VERSION ""

NS_ :

BS_:

BU_: Vector__XXX

BO_ 512 SM_Heartbeat: 8 Vector__XXX
SG_ SM_State : 0|8@1+ (1,0) [0|255] "" Vector__XXX
SG_ SM_Vbatt : 8|8@1+ (0.066666,0) [0|16.99983] "V" Vector__XXX
SG_ Target_State : 16|8@1+ (1,0) [0|255] "" Vector__XXX
SG_ CC_Heartbeat_Timed_Out : 24|1@1+ (1,0) [0|1] "" Vector__XXX
SG_ FSM_Heartbeat_Timed_Out : 25|1@1+ (1,0) [0|1] "" Vector__XXX
SG_ RSM_Heartbeat_Timed_Out : 26|1@1+ (1,0) [0|1] "" Vector__XXX
SG_ DIM_Heartbeat_Timed_Out : 27|1@1+ (1,0) [0|1] "" Vector__XXX
SG_ AFC_Heartbeat_Timed_Out : 28|1@1+ (1,0) [0|1] "" Vector__XXX
SG_ TM_Heartbeat_Timed_Out : 29|1@1+ (1,0) [0|1] "" Vector__XXX
SG_ CC_State_Timed_Out : 32|1@1+ (1,0) [0|1] "" Vector__XXX
SG_ FSM_State_Timed_Out : 33|1@1+ (1,0) [0|1] "" Vector__XXX
SG_ RSM_State_Timed_Out : 34|1@1+ (1,0) [0|1] "" Vector__XXX
SG_ DIM_State_Timed_Out : 35|1@1+ (1,0) [0|1] "" Vector__XXX
SG_ AFC_State_Timed_Out : 36|1@1+ (1,0) [0|1] "" Vector__XXX
SG_ TM_State_Timed_Out : 37|1@1+ (1,0) [0|1] "" Vector__XXX
SG_ IMD_ERROR : 40|1@1+ (1,0) [0|1] "" Vector__XXX
SG_ BMS_Error : 41|1@1+ (1,0) [0|1] "" Vector__XXX
SG_ BSPD_Error : 42|1@1+ (1,0) [0|1] "" Vector__XXX
SG_ Egress : 44|1@1+ (1,0) [0|1] "" Vector__XXX
SG_ Check : 43|1@1+ (1,0) [0|1] "" Vector__XXX
SG_ DCDC_ERROR : 45|1@1+ (1,0) [0|1] "" Vector__XXX
SG_ Cooling_State : 48|8@1+ (1,0) [0|255] "" Vector__XXX
SG_ Rear_Brake_Pressure : 56|8@1+ (1,0) [0|255] "" Vector__XXX

BO_ 513 CC_Heartbeat: 3 Vector__XXX
SG_ CC_State : 0|8@1+ (1,0) [0|255] "" Vector__XXX
SG_ CC_VBatt : 8|8@1+ (0.066666,0) [0|16.99983] "V" Vector__XXX
SG_ CC_Gear : 16|8@1+ (1,0) [0|255] "" Vector__XXX

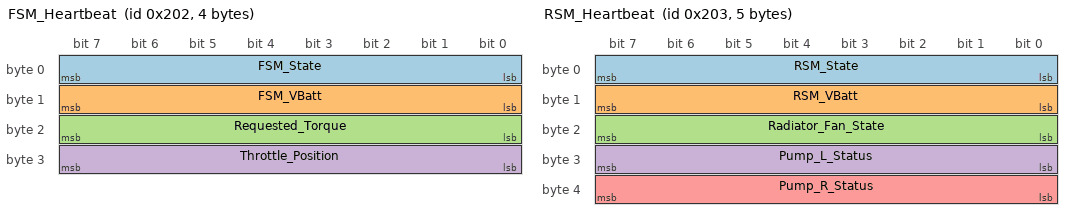
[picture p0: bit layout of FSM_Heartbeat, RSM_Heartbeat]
BO_ 514 FSM_Heartbeat: 4 Vector__XXX
SG_ FSM_State : 0|8@1+ (1,0) [0|255] "" Vector__XXX
SG_ FSM_VBatt : 8|8@1+ (0.066666,0) [0|16.99983] "V" Vector__XXX
SG_ Requested_Torque : 16|8@1+ (1,0) [0|255] "" Vector__XXX
SG_ Throttle_Position : 24|8@1+ (1,0) [0|255] "MPH" Vector__XXX

BO_ 515 RSM_Heartbeat: 5 Vector__XXX
SG_ RSM_State : 0|8@1+ (1,0) [0|255] "" Vector__XXX
SG_ RSM_VBatt : 8|8@1+ (0.066666,0) [0|16.99983] "" Vector__XXX
SG_ Radiator_Fan_State : 16|8@1+ (1,0) [0|255] "" Vector__XXX
SG_ Pump_L_Status : 24|8@1+ (1,0) [0|255] "" Vector__XXX
SG_ Pump_R_Status : 32|8@1+ (1,0) [0|255] "" Vector__XXX

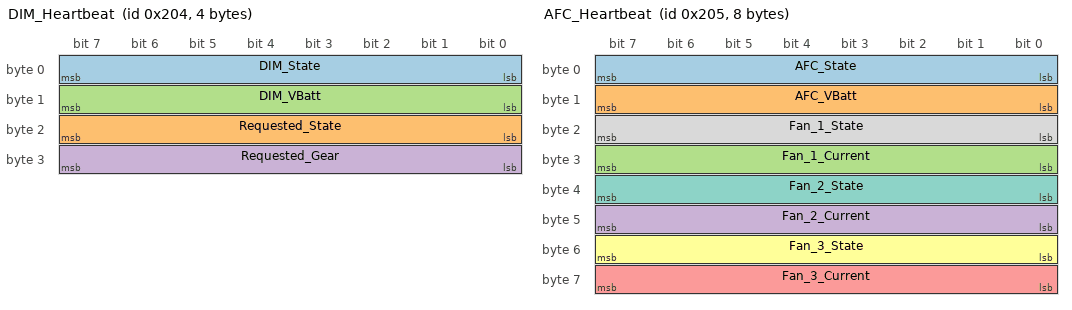
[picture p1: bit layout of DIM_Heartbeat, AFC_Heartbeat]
BO_ 516 DIM_Heartbeat: 4 Vector__XXX
SG_ DIM_State : 0|8@1+ (1,0) [0|255] "" Vector__XXX
SG_ Requested_State : 16|8@1+ (1,0) [0|255] "" Vector__XXX
SG_ DIM_VBatt : 8|8@1+ (0.066666,0) [0|16.99983] "V" Vector__XXX
SG_ Requested_Gear : 24|8@1+ (1,0) [0|255] "" Vector__XXX

BO_ 517 AFC_Heartbeat: 8 Vector__XXX
SG_ AFC_State : 0|8@1+ (1,0) [0|255] "" Vector__XXX
SG_ AFC_VBatt : 8|8@1+ (0.066666,0) [0|16.99983] "V" Vector__XXX
SG_ Fan_1_Current : 24|8@1+ (1,0) [0|255] "A" Vector__XXX
SG_ Fan_2_Current : 40|8@1+ (1,0) [0|255] "A" Vector__XXX
SG_ Fan_3_Current : 56|8@1+ (1,0) [0|255] "A" Vector__XXX
SG_ Fan_3_State : 48|8@1+ (1,0) [0|255] "" Vector__XXX
SG_ Fan_2_State : 32|8@1+ (1,0) [0|255] "" Vector__XXX
SG_ Fan_1_State : 16|8@1+ (1,0) [0|255] "" Vector__XXX

BO_ 518 TM_Heartbeat: 2 Vector__XXX
SG_ TM_State : 0|8@1+ (1,0) [0|255] "" Vector__XXX
SG_ TM_VBatt : 8|8@1+ (0.066666,0) [0|16.99983] "V" Vector__XXX

BO_ 519 Comms_Heartbeat: 2 Vector__XXX
SG_ Comms_State : 0|8@1+ (1,0) [0|255] "" Vector__XXX
SG_ Comms_VBatt : 8|8@1+ (0.066666,0) [0|16.99983] "V" Vector__XXX

BO_ 528 CMRduino_Heartbeat: 8 Vector__XXX
SG_ Comms_State : 0|8@1+ (1,0) [0|255] "" Vector__XXX
SG_ Comms_VBatt : 8|8@1+ (0.066666,0) [0|16.99983] "V" Vector__XXX

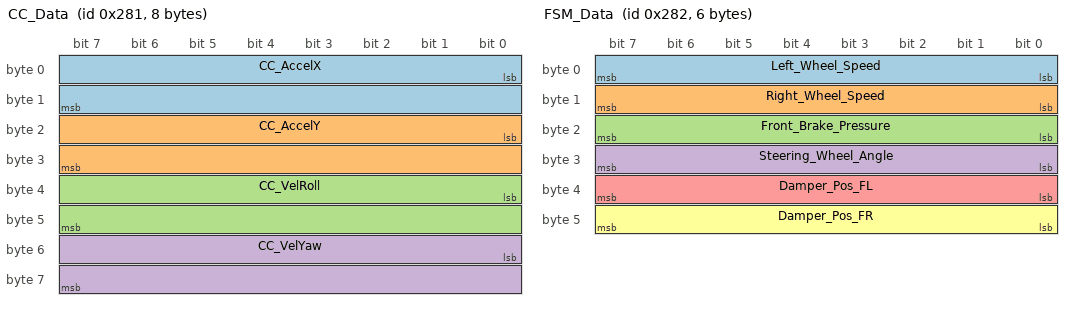
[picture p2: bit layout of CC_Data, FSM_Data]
BO_ 641 CC_Data: 8 Vector__XXX
SG_ CC_AccelX : 0|16@1- (0.0009765625,0) [-32|31.9990234375] "m/s^2" Vector__XXX
SG_ CC_AccelY : 16|16@1- (0.0009765625,0) [-32|31.9990234375] "m/s^2" Vector__XXX
SG_ CC_VelRoll : 32|16@1- (0.0009765625,0) [-32|31.9990234375] "rad/s" Vector__XXX
SG_ CC_VelYaw : 48|16@1- (0.0009765625,0) [-32|31.9990234375] "rad/s" Vector__XXX

BO_ 642 FSM_Data: 6 Vector__XXX
SG_ Left_Wheel_Speed : 0|8@1+ (7.763,0) [0|1979.565] "rpm" Vector__XXX
SG_ Right_Wheel_Speed : 8|8@1+ (7.763,0) [0|1979.565] "rpm" Vector__XXX
SG_ Front_Brake_Pressure : 16|8@1+ (1,0) [0|255] "" Vector__XXX
SG_ Steering_Wheel_Angle : 24|8@1+ (1,0) [0|255] "" Vector__XXX
SG_ Damper_Pos_FL : 32|8@1+ (1,0) [0|255] "" Vector__XXX
SG_ Damper_Pos_FR : 40|8@1+ (1,0) [0|255] "" Vector__XXX

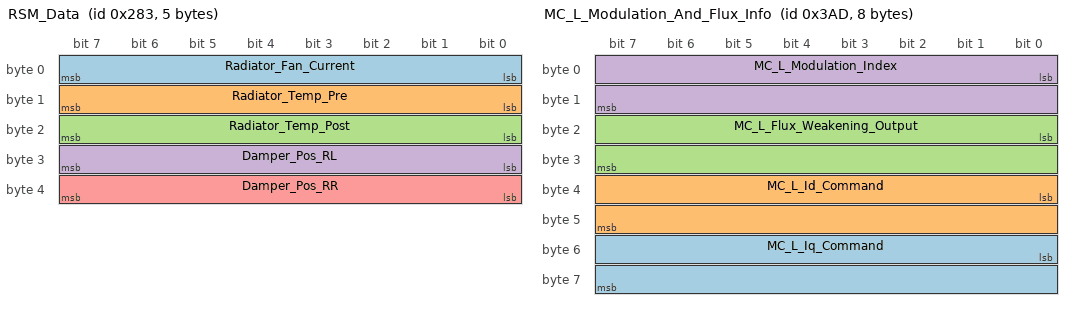
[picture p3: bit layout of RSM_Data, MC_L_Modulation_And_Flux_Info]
BO_ 643 RSM_Data: 5 Vector__XXX
SG_ Radiator_Fan_Current : 0|8@1+ (1,0) [0|255] "mA" Vector__XXX
SG_ Radiator_Temp_Pre : 8|8@1+ (1,0) [0|255] "degC" Vector__XXX
SG_ Radiator_Temp_Post : 16|8@1+ (1,0) [0|255] "degC" Vector__XXX
SG_ Damper_Pos_RL : 24|8@1+ (1,0) [0|255] "" Vector__XXX
SG_ Damper_Pos_RR : 32|8@1+ (1,0) [0|255] "" Vector__XXX

BO_ 941 MC_L_Modulation_And_Flux_Info: 8 Vector__XXX
SG_ MC_L_Iq_Command : 48|16@1- (0.1,0) [-3276.8|3276.7] "A" Vector__XXX
SG_ MC_L_Id_Command : 32|16@1- (0.1,0) [-3276.8|3276.7] "A" Vector__XXX
SG_ MC_L_Flux_Weakening_Output : 16|16@1- (0.1,0) [-3276.8|3276.7] "A" Vector__XXX
SG_ MC_L_Modulation_Index : 0|16@1- (0.0001,0) [-3.2768|3.2767] "" Vector__XXX

BO_ 940 MC_L_Torque_And_Timer_Info: 8 Vector__XXX
SG_ MC_L_Power_On_Timer : 32|32@1+ (0.003,0) [0|12884901.885] "Sec" Vector__XXX
SG_ MC_L_Torque_Feedback : 16|16@1- (0.1,0) [-3276.8|3276.7] "Nm" Vector__XXX
SG_ MC_L_Commanded_Torque : 0|16@1- (0.1,0) [-3276.8|3276.7] "Nm" Vector__XXX

BO_ 962 MC_L_Read_Write_Param_Response: 8 Vector__XXX
SG_ MC_L_Write_Success : 16|1@1+ (1,0) [0|1] "" Vector__XXX
SG_ MC_L_Data_Response : 32|16@1- (1,0) [-32768|32767] "" Vector__XXX
SG_ MC_L_Parameter_Address_Response : 0|16@1+ (1,0) [0|65535] "" Vector__XXX

BO_ 961 MC_L_Read_Write_Param_Command: 8 Vector__XXX
SG_ MC_L_Data_Command : 32|16@1- (1,0) [-32768|32767] "" Vector__XXX
SG_ MC_L_Read_Write_Command : 16|1@1+ (1,0) [0|1] "" Vector__XXX
SG_ MC_L_Parameter_Address_Command : 0|16@1+ (1,0) [0|65535] "" Vector__XXX

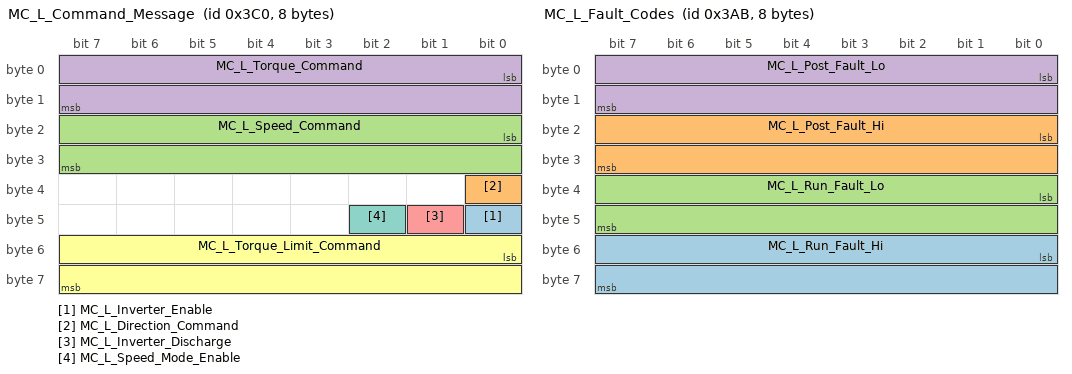
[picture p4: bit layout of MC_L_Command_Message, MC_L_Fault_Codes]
BO_ 960 MC_L_Command_Message: 8 Vector__XXX
SG_ MC_L_Inverter_Enable : 40|1@1+ (1,0) [0|1] "Bit" Vector__XXX
SG_ MC_L_Direction_Command : 32|1@1+ (1,0) [0|1] "Bit" Vector__XXX
SG_ MC_L_Speed_Command : 16|16@1- (1,0) [-32768|32767] "rpm" Vector__XXX
SG_ MC_L_Torque_Command : 0|16@1- (0.1,0) [-3276.8|3276.7] "Nm" Vector__XXX
SG_ MC_L_Inverter_Discharge : 41|1@1+ (1,0) [0|1] "Bit" Vector__XXX
SG_ MC_L_Torque_Limit_Command : 48|16@1- (1,0) [-3276.8|3276.7] "Nm" Vector__XXX
SG_ MC_L_Speed_Mode_Enable : 42|1@1+ (1,0) [0|1] "Bit" Vector__XXX

BO_ 939 MC_L_Fault_Codes: 8 Vector__XXX
SG_ MC_L_Run_Fault_Hi : 48|16@1+ (1,0) [0|65535] "" Vector__XXX
SG_ MC_L_Post_Fault_Hi : 16|16@1+ (1,0) [0|65535] "" Vector__XXX
SG_ MC_L_Run_Fault_Lo : 32|16@1+ (1,0) [0|65535] "" Vector__XXX
SG_ MC_L_Post_Fault_Lo : 0|16@1+ (1,0) [0|65535] "" Vector__XXX

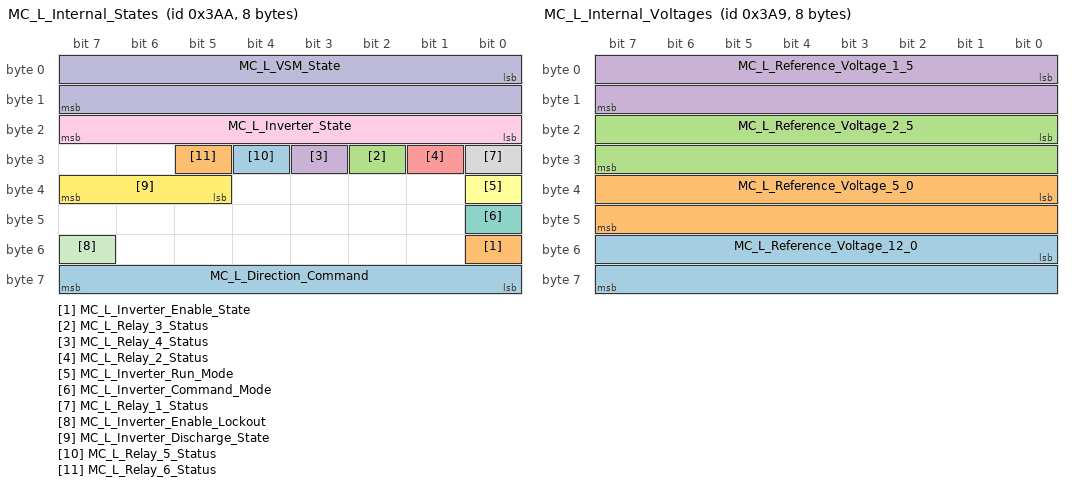
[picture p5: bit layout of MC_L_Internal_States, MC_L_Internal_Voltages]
BO_ 938 MC_L_Internal_States: 8 Vector__XXX
SG_ MC_L_Direction_Command : 56|8@1+ (1,0) [0|1] "" Vector__XXX
SG_ MC_L_Inverter_Enable_State : 48|1@1+ (1,0) [0|1] "" Vector__XXX
SG_ MC_L_Relay_3_Status : 26|1@1+ (1,0) [0|1] "" Vector__XXX
SG_ MC_L_Relay_4_Status : 27|1@1+ (1,0) [0|1] "" Vector__XXX
SG_ MC_L_Relay_2_Status : 25|1@1+ (1,0) [0|1] "" Vector__XXX
SG_ MC_L_Inverter_Run_Mode : 32|1@1+ (1,0) [0|1] "" Vector__XXX
SG_ MC_L_Inverter_Command_Mode : 40|1@1+ (1,0) [0|1] "" Vector__XXX
SG_ MC_L_Relay_1_Status : 24|1@1+ (1,0) [0|1] "" Vector__XXX
SG_ MC_L_Inverter_State : 16|8@1+ (1,0) [0|255] "" Vector__XXX
SG_ MC_L_VSM_State : 0|16@1+ (1,0) [0|15] "" Vector__XXX
SG_ MC_L_Inverter_Enable_Lockout : 55|1@1+ (1,0) [0|1] "" Vector__XXX
SG_ MC_L_Inverter_Discharge_State : 37|3@1+ (1,0) [0|7] "" Vector__XXX
SG_ MC_L_Relay_5_Status : 28|1@1+ (1,0) [0|1] "" Vector__XXX
SG_ MC_L_Relay_6_Status : 29|1@1+ (1,0) [0|1] "" Vector__XXX

BO_ 937 MC_L_Internal_Voltages: 8 Vector__XXX
SG_ MC_L_Reference_Voltage_12_0 : 48|16@1- (0.01,0) [-327.68|327.67] "V" Vector__XXX
SG_ MC_L_Reference_Voltage_5_0 : 32|16@1- (0.01,0) [-327.68|327.67] "V" Vector__XXX
SG_ MC_L_Reference_Voltage_2_5 : 16|16@1- (0.01,0) [-327.68|327.67] "V" Vector__XXX
SG_ MC_L_Reference_Voltage_1_5 : 0|16@1- (0.01,0) [-327.68|327.67] "V" Vector__XXX

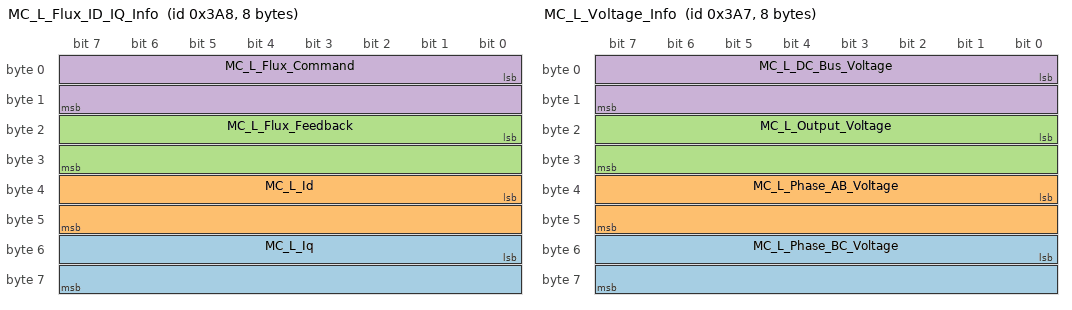
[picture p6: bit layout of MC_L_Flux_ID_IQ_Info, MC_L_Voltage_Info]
BO_ 936 MC_L_Flux_ID_IQ_Info: 8 Vector__XXX
SG_ MC_L_Iq : 48|16@1- (0.1,0) [-3276.8|3276.7] "A" Vector__XXX
SG_ MC_L_Id : 32|16@1- (0.1,0) [-3276.8|3276.7] "A" Vector__XXX
SG_ MC_L_Flux_Feedback : 16|16@1- (0.001,0) [-32.768|32.767] "Wb" Vector__XXX
SG_ MC_L_Flux_Command : 0|16@1- (0.001,0) [-32.768|32.767] "Wb" Vector__XXX

BO_ 935 MC_L_Voltage_Info: 8 Vector__XXX
SG_ MC_L_Phase_BC_Voltage : 48|16@1- (0.1,0) [-3276.8|3276.7] "V" Vector__XXX
SG_ MC_L_Phase_AB_Voltage : 32|16@1- (0.1,0) [-3276.8|3276.7] "V" Vector__XXX
SG_ MC_L_Output_Voltage : 16|16@1- (0.1,0) [-3276.8|3276.7] "V" Vector__XXX
SG_ MC_L_DC_Bus_Voltage : 0|16@1- (0.1,0) [-3276.8|3276.7] "V" Vector__XXX

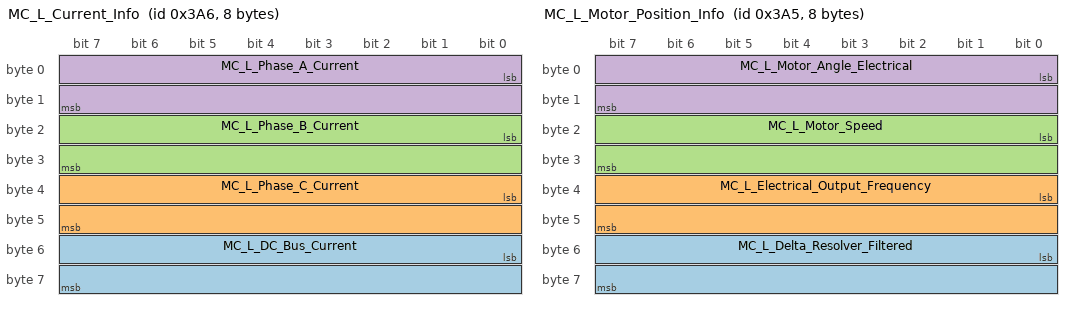
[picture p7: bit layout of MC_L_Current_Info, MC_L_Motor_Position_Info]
BO_ 934 MC_L_Current_Info: 8 Vector__XXX
SG_ MC_L_DC_Bus_Current : 48|16@1- (0.1,0) [-3276.8|3276.7] "A" Vector__XXX
SG_ MC_L_Phase_C_Current : 32|16@1- (0.1,0) [-3276.8|3276.7] "A" Vector__XXX
SG_ MC_L_Phase_B_Current : 16|16@1- (0.1,0) [-3276.8|3276.7] "A" Vector__XXX
SG_ MC_L_Phase_A_Current : 0|16@1- (0.1,0) [-3276.8|3276.7] "A" Vector__XXX

BO_ 933 MC_L_Motor_Position_Info: 8 Vector__XXX
SG_ MC_L_Delta_Resolver_Filtered : 48|16@1- (0.1,0) [-3276.8|3276.7] "deg" Vector__XXX
SG_ MC_L_Electrical_Output_Frequency : 32|16@1- (0.1,0) [-3276.8|3276.7] "hz" Vector__XXX
SG_ MC_L_Motor_Speed : 16|16@1- (-1,0) [-32767|32768] "rpm" Vector__XXX
SG_ MC_L_Motor_Angle_Electrical : 0|16@1+ (0.1,0) [0|6553.5] "deg" Vector__XXX

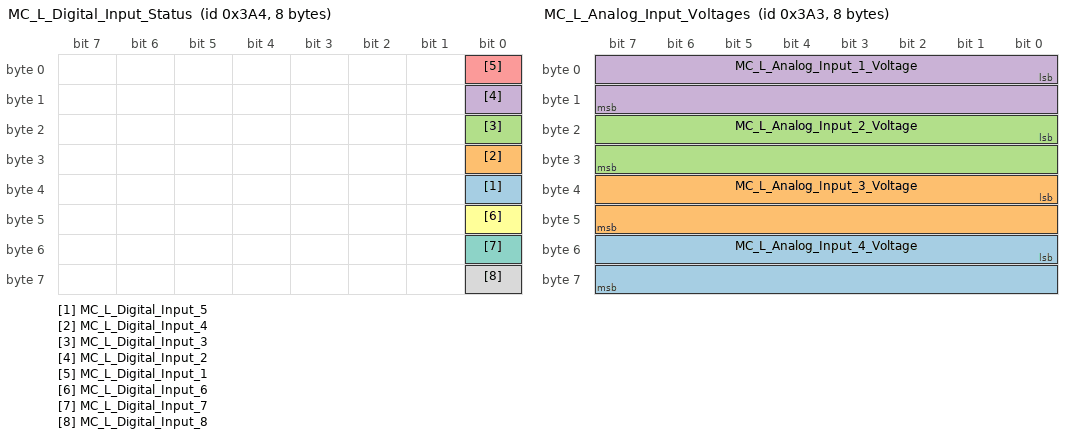
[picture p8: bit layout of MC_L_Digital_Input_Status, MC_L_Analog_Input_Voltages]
BO_ 932 MC_L_Digital_Input_Status: 8 Vector__XXX
SG_ MC_L_Digital_Input_5 : 32|1@1+ (1,0) [0|1] "boolean" Vector__XXX
SG_ MC_L_Digital_Input_4 : 24|1@1+ (1,0) [0|1] "boolean" Vector__XXX
SG_ MC_L_Digital_Input_3 : 16|1@1+ (1,0) [0|1] "boolean" Vector__XXX
SG_ MC_L_Digital_Input_2 : 8|1@1+ (1,0) [0|1] "boolean" Vector__XXX
SG_ MC_L_Digital_Input_1 : 0|1@1+ (1,0) [0|1] "boolean" Vector__XXX
SG_ MC_L_Digital_Input_6 : 40|1@1+ (1,0) [0|1] "boolean" Vector__XXX
SG_ MC_L_Digital_Input_7 : 48|1@1+ (1,0) [0|1] "boolean" Vector__XXX
SG_ MC_L_Digital_Input_8 : 56|1@1+ (1,0) [0|1] "boolean" Vector__XXX

BO_ 931 MC_L_Analog_Input_Voltages: 8 Vector__XXX
SG_ MC_L_Analog_Input_4_Voltage : 48|16@1- (0.01,0) [-327.68|327.67] "V" Vector__XXX
SG_ MC_L_Analog_Input_3_Voltage : 32|16@1- (0.01,0) [-327.68|327.67] "V" Vector__XXX
SG_ MC_L_Analog_Input_2_Voltage : 16|16@1- (0.01,0) [-327.68|327.67] "V" Vector__XXX
SG_ MC_L_Analog_Input_1_Voltage : 0|16@1- (0.01,0) [-327.68|327.67] "V" Vector__XXX

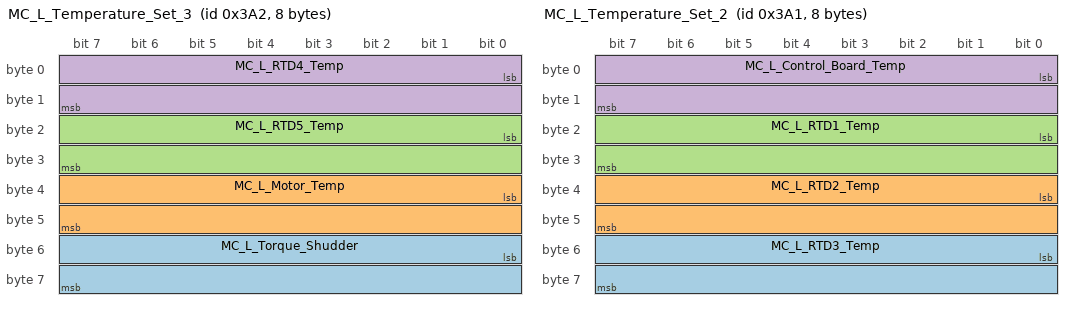
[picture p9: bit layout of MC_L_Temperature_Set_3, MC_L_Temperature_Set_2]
BO_ 930 MC_L_Temperature_Set_3: 8 Vector__XXX
SG_ MC_L_Torque_Shudder : 48|16@1- (0.1,0) [-3276.8|3276.7] "Nm" Vector__XXX
SG_ MC_L_Motor_Temp : 32|16@1- (0.1,0) [-3276.8|3276.7] "degC" Vector__XXX
SG_ MC_L_RTD5_Temp : 16|16@1- (0.1,0) [-3276.8|3276.7] "degC" Vector__XXX
SG_ MC_L_RTD4_Temp : 0|16@1- (0.1,0) [-3276.8|3276.7] "degC" Vector__XXX

BO_ 929 MC_L_Temperature_Set_2: 8 Vector__XXX
SG_ MC_L_RTD3_Temp : 48|16@1- (0.1,0) [-3276.8|3276.7] "degC" Vector__XXX
SG_ MC_L_RTD2_Temp : 32|16@1- (0.1,0) [-3276.8|3276.7] "degC" Vector__XXX
SG_ MC_L_RTD1_Temp : 16|16@1- (0.1,0) [-3276.8|3276.7] "degC" Vector__XXX
SG_ MC_L_Control_Board_Temp : 0|16@1- (0.1,0) [-3276.8|3276.7] "degC" Vector__XXX

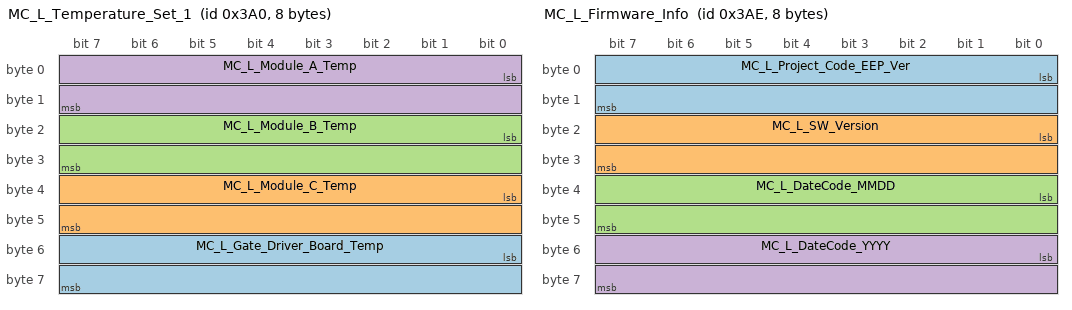
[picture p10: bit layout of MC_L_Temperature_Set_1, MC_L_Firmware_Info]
BO_ 928 MC_L_Temperature_Set_1: 8 Vector__XXX
SG_ MC_L_Gate_Driver_Board_Temp : 48|16@1- (0.1,0) [-3276.8|3276.7] "degC" Vector__XXX
SG_ MC_L_Module_C_Temp : 32|16@1- (0.1,0) [-3276.8|3276.7] "degC" Vector__XXX
SG_ MC_L_Module_B_Temp : 16|16@1- (0.1,0) [-3276.8|3276.7] "degC" Vector__XXX
SG_ MC_L_Module_A_Temp : 0|16@1- (0.1,0) [-3276.8|3276.7] "degC" Vector__XXX

BO_ 942 MC_L_Firmware_Info: 8 Vector__XXX
SG_ MC_L_Project_Code_EEP_Ver : 0|16@1+ (1,0) [0|65535] "" Vector__XXX
SG_ MC_L_SW_Version : 16|16@1+ (1,0) [0|65535] "" Vector__XXX
SG_ MC_L_DateCode_MMDD : 32|16@1+ (1,0) [0|65535] "" Vector__XXX
SG_ MC_L_DateCode_YYYY : 48|16@1+ (1,0) [0|65535] "" Vector__XXX

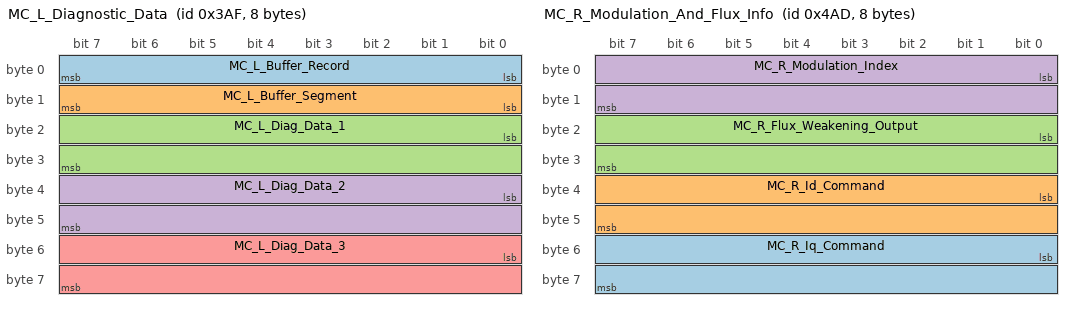
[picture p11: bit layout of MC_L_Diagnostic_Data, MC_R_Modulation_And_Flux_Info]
BO_ 943 MC_L_Diagnostic_Data: 8 Vector__XXX
SG_ MC_L_Buffer_Record : 0|8@1+ (1,0) [0|160] "" Vector__XXX
SG_ MC_L_Buffer_Segment : 8|8@1+ (1,0) [0|5] "" Vector__XXX
SG_ MC_L_Diag_Data_1 : 16|16@1- (1,0) [0|32767] "" Vector__XXX
SG_ MC_L_Diag_Data_2 : 32|16@1- (1,0) [0|32767] "" Vector__XXX
SG_ MC_L_Diag_Data_3 : 48|16@1- (1,0) [0|32767] "" Vector__XXX

BO_ 1197 MC_R_Modulation_And_Flux_Info: 8 Vector__XXX
SG_ MC_R_Iq_Command : 48|16@1- (0.1,0) [-3276.8|3276.7] "A" Vector__XXX
SG_ MC_R_Id_Command : 32|16@1- (0.1,0) [-3276.8|3276.7] "A" Vector__XXX
SG_ MC_R_Flux_Weakening_Output : 16|16@1- (0.1,0) [-3276.8|3276.7] "A" Vector__XXX
SG_ MC_R_Modulation_Index : 0|16@1- (0.0001,0) [-3.2768|3.2767] "" Vector__XXX

BO_ 1196 MC_R_Torque_And_Timer_Info: 8 Vector__XXX
SG_ MC_R_Power_On_Timer : 32|32@1+ (0.003,0) [0|12884901.885] "Sec" Vector__XXX
SG_ MC_R_Torque_Feedback : 16|16@1- (0.1,0) [-3276.8|3276.7] "Nm" Vector__XXX
SG_ MC_R_Commanded_Torque : 0|16@1- (0.1,0) [-3276.8|3276.7] "Nm" Vector__XXX

BO_ 1218 MC_R_Read_Write_Param_Response: 8 Vector__XXX
SG_ MC_R_Write_Success : 16|1@1+ (1,0) [0|1] "" Vector__XXX
SG_ MC_R_Data_Response : 32|16@1- (1,0) [-32768|32767] "" Vector__XXX
SG_ MC_R_Parameter_Address_Response : 0|16@1+ (1,0) [0|65535] "" Vector__XXX

BO_ 1217 MC_R_Read_Write_Param_Command: 8 Vector__XXX
SG_ MC_R_Data_Command : 32|16@1- (1,0) [-32768|32767] "" Vector__XXX
SG_ MC_R_Read_Write_Command : 16|1@1+ (1,0) [0|1] "" Vector__XXX
SG_ MC_R_Parameter_Address_Command : 0|16@1+ (1,0) [0|65535] "" Vector__XXX

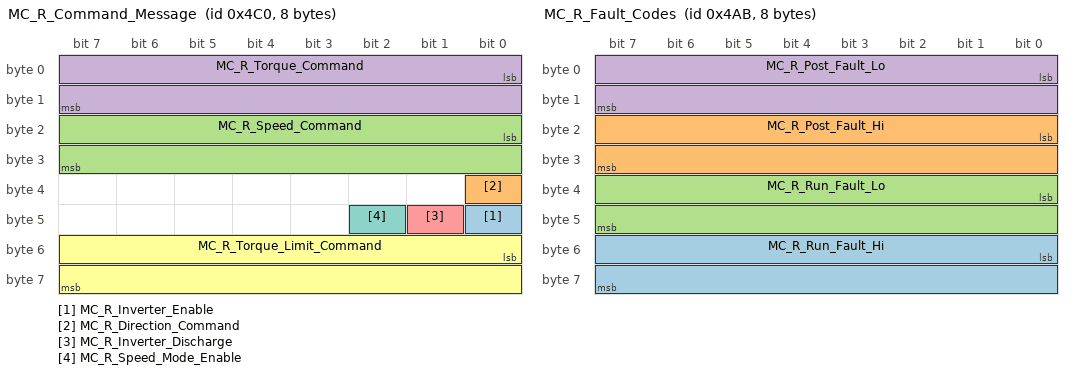
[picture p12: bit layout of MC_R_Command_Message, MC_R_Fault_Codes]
BO_ 1216 MC_R_Command_Message: 8 Vector__XXX
SG_ MC_R_Inverter_Enable : 40|1@1+ (1,0) [0|1] "Bit" Vector__XXX
SG_ MC_R_Direction_Command : 32|1@1+ (1,0) [0|1] "Bit" Vector__XXX
SG_ MC_R_Speed_Command : 16|16@1- (1,0) [-32768|32767] "rpm" Vector__XXX
SG_ MC_R_Torque_Command : 0|16@1- (0.1,0) [-3276.8|3276.7] "Nm" Vector__XXX
SG_ MC_R_Inverter_Discharge : 41|1@1+ (1,0) [0|1] "Bit" Vector__XXX
SG_ MC_R_Torque_Limit_Command : 48|16@1- (1,0) [-3276.8|3276.7] "Nm" Vector__XXX
SG_ MC_R_Speed_Mode_Enable : 42|1@1+ (1,0) [0|1] "Bit" Vector__XXX

BO_ 1195 MC_R_Fault_Codes: 8 Vector__XXX
SG_ MC_R_Run_Fault_Hi : 48|16@1+ (1,0) [0|65535] "" Vector__XXX
SG_ MC_R_Post_Fault_Hi : 16|16@1+ (1,0) [0|65535] "" Vector__XXX
SG_ MC_R_Run_Fault_Lo : 32|16@1+ (1,0) [0|65535] "" Vector__XXX
SG_ MC_R_Post_Fault_Lo : 0|16@1+ (1,0) [0|65535] "" Vector__XXX

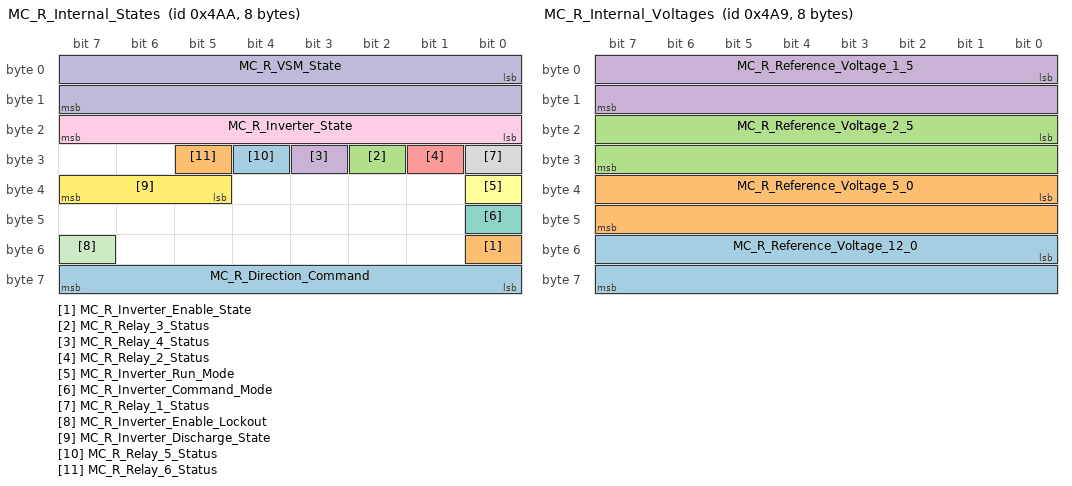
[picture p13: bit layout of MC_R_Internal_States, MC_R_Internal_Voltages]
BO_ 1194 MC_R_Internal_States: 8 Vector__XXX
SG_ MC_R_Direction_Command : 56|8@1+ (1,0) [0|1] "" Vector__XXX
SG_ MC_R_Inverter_Enable_State : 48|1@1+ (1,0) [0|1] "" Vector__XXX
SG_ MC_R_Relay_3_Status : 26|1@1+ (1,0) [0|1] "" Vector__XXX
SG_ MC_R_Relay_4_Status : 27|1@1+ (1,0) [0|1] "" Vector__XXX
SG_ MC_R_Relay_2_Status : 25|1@1+ (1,0) [0|1] "" Vector__XXX
SG_ MC_R_Inverter_Run_Mode : 32|1@1+ (1,0) [0|1] "" Vector__XXX
SG_ MC_R_Inverter_Command_Mode : 40|1@1+ (1,0) [0|1] "" Vector__XXX
SG_ MC_R_Relay_1_Status : 24|1@1+ (1,0) [0|1] "" Vector__XXX
SG_ MC_R_Inverter_State : 16|8@1+ (1,0) [0|255] "" Vector__XXX
SG_ MC_R_VSM_State : 0|16@1+ (1,0) [0|15] "" Vector__XXX
SG_ MC_R_Inverter_Enable_Lockout : 55|1@1+ (1,0) [0|1] "" Vector__XXX
SG_ MC_R_Inverter_Discharge_State : 37|3@1+ (1,0) [0|7] "" Vector__XXX
SG_ MC_R_Relay_5_Status : 28|1@1+ (1,0) [0|1] "" Vector__XXX
SG_ MC_R_Relay_6_Status : 29|1@1+ (1,0) [0|1] "" Vector__XXX

BO_ 1193 MC_R_Internal_Voltages: 8 Vector__XXX
SG_ MC_R_Reference_Voltage_12_0 : 48|16@1- (0.01,0) [-327.68|327.67] "V" Vector__XXX
SG_ MC_R_Reference_Voltage_5_0 : 32|16@1- (0.01,0) [-327.68|327.67] "V" Vector__XXX
SG_ MC_R_Reference_Voltage_2_5 : 16|16@1- (0.01,0) [-327.68|327.67] "V" Vector__XXX
SG_ MC_R_Reference_Voltage_1_5 : 0|16@1- (0.01,0) [-327.68|327.67] "V" Vector__XXX

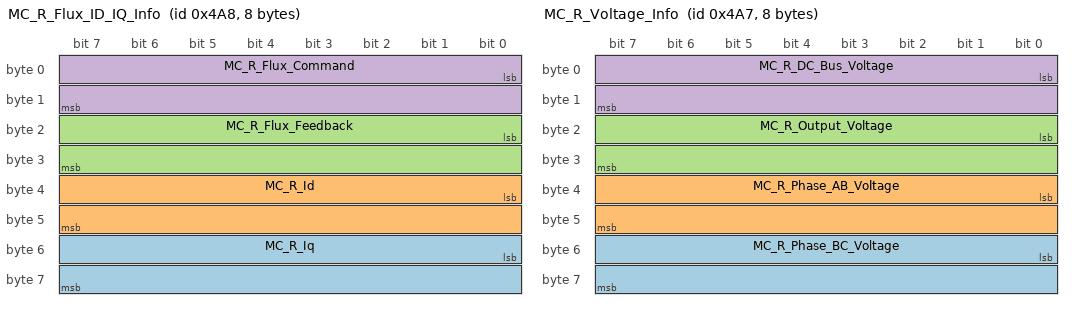
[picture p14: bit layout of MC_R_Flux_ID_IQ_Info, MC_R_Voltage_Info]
BO_ 1192 MC_R_Flux_ID_IQ_Info: 8 Vector__XXX
SG_ MC_R_Iq : 48|16@1- (0.1,0) [-3276.8|3276.7] "A" Vector__XXX
SG_ MC_R_Id : 32|16@1- (0.1,0) [-3276.8|3276.7] "A" Vector__XXX
SG_ MC_R_Flux_Feedback : 16|16@1- (0.001,0) [-32.768|32.767] "Wb" Vector__XXX
SG_ MC_R_Flux_Command : 0|16@1- (0.001,0) [-32.768|32.767] "Wb" Vector__XXX

BO_ 1191 MC_R_Voltage_Info: 8 Vector__XXX
SG_ MC_R_Phase_BC_Voltage : 48|16@1- (0.1,0) [-3276.8|3276.7] "V" Vector__XXX
SG_ MC_R_Phase_AB_Voltage : 32|16@1- (0.1,0) [-3276.8|3276.7] "V" Vector__XXX
SG_ MC_R_Output_Voltage : 16|16@1- (0.1,0) [-3276.8|3276.7] "V" Vector__XXX
SG_ MC_R_DC_Bus_Voltage : 0|16@1- (0.1,0) [-3276.8|3276.7] "V" Vector__XXX

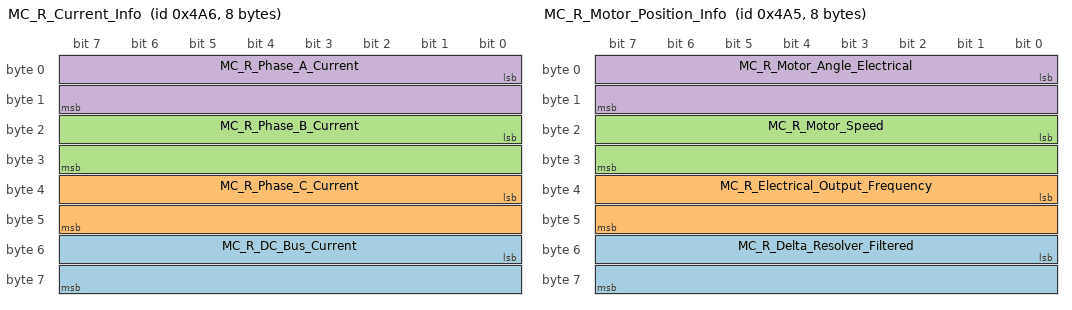
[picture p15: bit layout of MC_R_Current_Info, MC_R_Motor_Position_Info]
BO_ 1190 MC_R_Current_Info: 8 Vector__XXX
SG_ MC_R_DC_Bus_Current : 48|16@1- (0.1,0) [-3276.8|3276.7] "A" Vector__XXX
SG_ MC_R_Phase_C_Current : 32|16@1- (0.1,0) [-3276.8|3276.7] "A" Vector__XXX
SG_ MC_R_Phase_B_Current : 16|16@1- (0.1,0) [-3276.8|3276.7] "A" Vector__XXX
SG_ MC_R_Phase_A_Current : 0|16@1- (0.1,0) [-3276.8|3276.7] "A" Vector__XXX

BO_ 1189 MC_R_Motor_Position_Info: 8 Vector__XXX
SG_ MC_R_Delta_Resolver_Filtered : 48|16@1- (0.1,0) [-3276.8|3276.7] "deg" Vector__XXX
SG_ MC_R_Electrical_Output_Frequency : 32|16@1- (0.1,0) [-3276.8|3276.7] "hz" Vector__XXX
SG_ MC_R_Motor_Speed : 16|16@1- (1,0) [-32768|32767] "rpm" Vector__XXX
SG_ MC_R_Motor_Angle_Electrical : 0|16@1+ (0.1,0) [0|6553.5] "deg" Vector__XXX

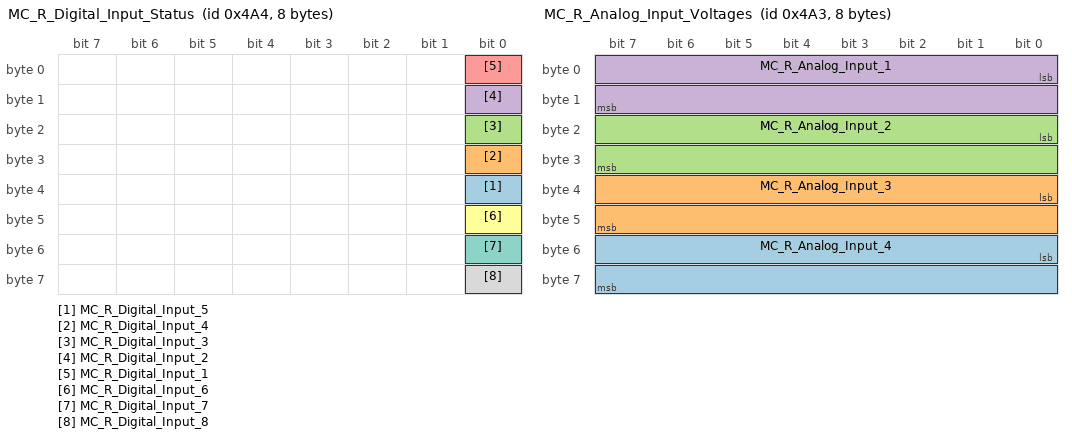
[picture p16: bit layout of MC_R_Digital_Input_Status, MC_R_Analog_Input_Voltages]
BO_ 1188 MC_R_Digital_Input_Status: 8 Vector__XXX
SG_ MC_R_Digital_Input_5 : 32|1@1+ (1,0) [0|1] "boolean" Vector__XXX
SG_ MC_R_Digital_Input_4 : 24|1@1+ (1,0) [0|1] "boolean" Vector__XXX
SG_ MC_R_Digital_Input_3 : 16|1@1+ (1,0) [0|1] "boolean" Vector__XXX
SG_ MC_R_Digital_Input_2 : 8|1@1+ (1,0) [0|1] "boolean" Vector__XXX
SG_ MC_R_Digital_Input_1 : 0|1@1+ (1,0) [0|1] "boolean" Vector__XXX
SG_ MC_R_Digital_Input_6 : 40|1@1+ (1,0) [0|1] "boolean" Vector__XXX
SG_ MC_R_Digital_Input_7 : 48|1@1+ (1,0) [0|1] "boolean" Vector__XXX
SG_ MC_R_Digital_Input_8 : 56|1@1+ (1,0) [0|1] "boolean" Vector__XXX

BO_ 1187 MC_R_Analog_Input_Voltages: 8 Vector__XXX
SG_ MC_R_Analog_Input_4 : 48|16@1- (0.01,0) [-327.68|327.67] "V" Vector__XXX
SG_ MC_R_Analog_Input_3 : 32|16@1- (0.01,0) [-327.68|327.67] "V" Vector__XXX
SG_ MC_R_Analog_Input_2 : 16|16@1- (0.01,0) [-327.68|327.67] "V" Vector__XXX
SG_ MC_R_Analog_Input_1 : 0|16@1- (0.01,0) [-327.68|327.67] "V" Vector__XXX

BO_ 1186 MC_R_Temperature_Set_3: 8 Vector__XXX
SG_ MC_R_Torque_Shudder : 48|16@1- (0.1,0) [-3276.8|3276.7] "Nm" Vector__XXX
SG_ MC_R_Motor_Temp : 32|16@1- (0.1,0) [-3276.8|3276.7] "degC" Vector__XXX
SG_ MC_R_RTD5_Temp : 16|16@1- (0.1,0) [-3276.8|3276.7] "degC" Vector__XXX
SG_ MC_R_RTD4_Temp : 0|16@1- (0.1,0) [-3276.8|3276.7] "degC" Vector__XXX

BO_ 1185 MC_R_Temperature_Set_2: 8 Vector__XXX
SG_ MC_R_RTD3_Temp : 48|16@1- (0.1,0) [-3276.8|3276.7] "degC" Vector__XXX
SG_ MC_R_RTD2_Temp : 32|16@1- (0.1,0) [-3276.8|3276.7] "degC" Vector__XXX
SG_ MC_R_RTD1_Temp : 16|16@1- (0.1,0) [-3276.8|3276.7] "degC" Vector__XXX
SG_ MC_R_Control_Board_Temp : 0|16@1- (0.1,0) [-3276.8|3276.7] "degC" Vector__XXX

BO_ 1184 MC_R_Temperature_Set_1: 8 Vector__XXX
SG_ MC_R_Gate_Driver_Board_Temp : 48|16@1- (0.1,0) [-3276.8|3276.7] "degC" Vector__XXX
SG_ MC_R_Module_C_Temp : 32|16@1- (0.1,0) [-3276.8|3276.7] "degC" Vector__XXX
SG_ MC_R_Module_B_Temp : 16|16@1- (0.1,0) [-3276.8|3276.7] "degC" Vector__XXX
SG_ MC_R_Module_A_Temp : 0|16@1- (0.1,0) [-3276.8|3276.7] "degC" Vector__XXX

BO_ 1198 MC_R_Firmware_Info: 8 Vector__XXX
SG_ MC_R_Project_Code_EEP_Ver : 0|16@1+ (1,0) [0|65535] "" Vector__XXX
SG_ MC_R_SW_Version : 16|16@1+ (1,0) [0|65535] "" Vector__XXX
SG_ MC_R_DateCode_MMDD : 32|16@1+ (1,0) [0|65535] "" Vector__XXX
SG_ MC_R_DateCode_YYYY : 48|16@1+ (1,0) [0|65535] "" Vector__XXX

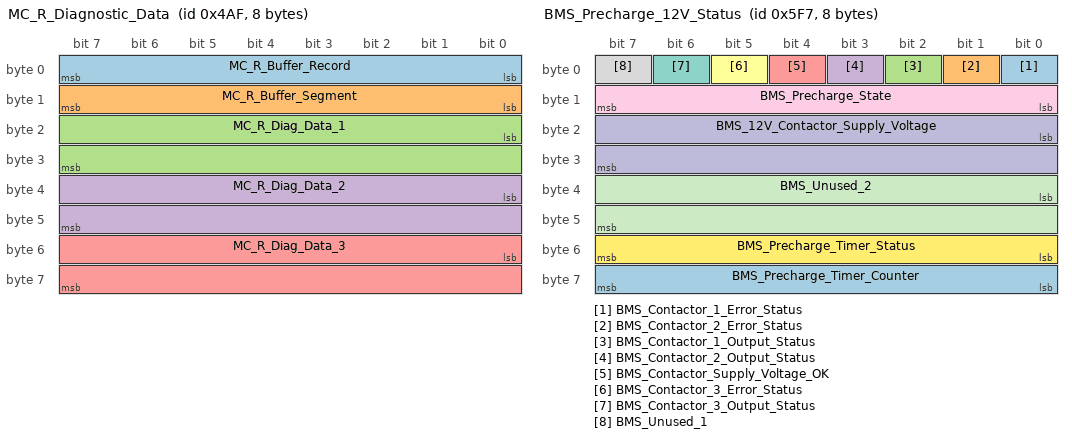
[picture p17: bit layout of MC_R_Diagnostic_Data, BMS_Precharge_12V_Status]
BO_ 1199 MC_R_Diagnostic_Data: 8 Vector__XXX
SG_ MC_R_Buffer_Record : 0|8@1+ (1,0) [0|160] "" Vector__XXX
SG_ MC_R_Buffer_Segment : 8|8@1+ (1,0) [0|5] "" Vector__XXX
SG_ MC_R_Diag_Data_1 : 16|16@1- (1,0) [0|32767] "" Vector__XXX
SG_ MC_R_Diag_Data_2 : 32|16@1- (1,0) [0|32767] "" Vector__XXX
SG_ MC_R_Diag_Data_3 : 48|16@1- (1,0) [0|32767] "" Vector__XXX

BO_ 1280 BMS_BMU_Heartbeat: 8 Vector__XXX
SG_ Device_ID : 0|32@1+ (1,0) [0|4294967295] "" Vector__XXX
SG_ Device_Serial : 32|32@1+ (1,0) [0|4294967295] "" Vector__XXX

BO_ 1520 BMS_Factory_Config_Calibration: 8 Vector__XXX

BO_ 1524 BMS_Pack_SOC: 8 Vector__XXX
SG_ BMS_Pack_SOC_Ah : 0|32@1- (1,0) [-3.4E038|3.4E038] "Ah" Vector__XXX
SG_ BMS_Pack_SOC_Percent : 32|32@1+ (1,0) [0|4294967295] "%" Vector__XXX

BO_ 1525 BMS_Balance_SOC: 8 Vector__XXX
SG_ BMS_Balance_SOC_Ah : 0|32@1- (1,0) [-3.4E038|3.4E038] "Ah" Vector__XXX
SG_ BMS_Balance_SOC_Percent : 32|32@1- (1,0) [-3.4E038|3.4E038] "%" Vector__XXX

BO_ 1526 BMS_Charger_Control_Info: 8 Vector__XXX
SG_ BMS_Charging_Cell_Voltage_Error : 0|16@1+ (1,0) [0|65535] "mV" Vector__XXX
SG_ BMS_Cell_Temp_Margin : 16|16@1+ (1,0) [0|65535] "1/10 C" Vector__XXX
SG_ BMS_Discharge_Cell_Voltage_Error : 32|16@1+ (1,0) [0|65535] "mV" Vector__XXX
SG_ BMS_Total_Pack_Capacity : 48|16@1+ (1,0) [0|65535] "Ah" Vector__XXX

BO_ 1527 BMS_Precharge_12V_Status: 8 Vector__XXX
SG_ BMS_Contactor_1_Error_Status : 0|1@1+ (1,0) [0|1] "" Vector__XXX
SG_ BMS_Contactor_2_Error_Status : 1|1@1+ (1,0) [0|1] "" Vector__XXX
SG_ BMS_Contactor_1_Output_Status : 2|1@1+ (1,0) [0|1] "" Vector__XXX
SG_ BMS_Contactor_2_Output_Status : 3|1@1+ (1,0) [0|1] "" Vector__XXX
SG_ BMS_Contactor_Supply_Voltage_OK : 4|1@1+ (1,0) [0|1] "" Vector__XXX
SG_ BMS_Contactor_3_Error_Status : 5|1@1+ (1,0) [0|1] "" Vector__XXX
SG_ BMS_Contactor_3_Output_Status : 6|1@1+ (1,0) [0|1] "" Vector__XXX
SG_ BMS_Unused_1 : 7|1@1+ (1,0) [0|1] "" Vector__XXX
SG_ BMS_Precharge_State : 8|8@1+ (1,0) [0|255] "" Vector__XXX
SG_ BMS_12V_Contactor_Supply_Voltage : 16|16@1+ (1,0) [0|65535] "mV" Vector__XXX
SG_ BMS_Unused_2 : 32|16@1+ (1,0) [0|65535] "" Vector__XXX
SG_ BMS_Precharge_Timer_Status : 48|8@1+ (1,0) [0|255] "" Vector__XXX
SG_ BMS_Precharge_Timer_Counter : 56|8@1+ (1,0) [0|255] "" Vector__XXX

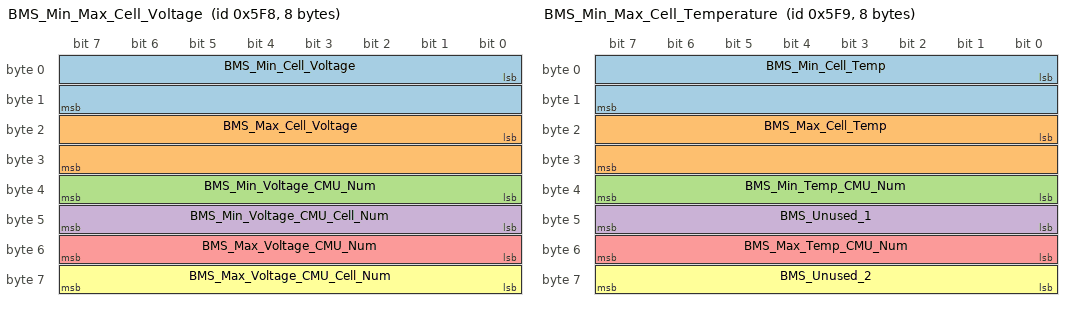
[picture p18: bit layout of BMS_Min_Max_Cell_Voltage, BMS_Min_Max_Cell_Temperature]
BO_ 1528 BMS_Min_Max_Cell_Voltage: 8 Vector__XXX
SG_ BMS_Min_Cell_Voltage : 0|16@1+ (1,0) [0|65535] "mV" Vector__XXX
SG_ BMS_Max_Cell_Voltage : 16|16@1+ (1,0) [0|65535] "mV" Vector__XXX
SG_ BMS_Min_Voltage_CMU_Num : 32|8@1+ (1,0) [0|255] "" Vector__XXX
SG_ BMS_Min_Voltage_CMU_Cell_Num : 40|8@1+ (1,0) [0|255] "" Vector__XXX
SG_ BMS_Max_Voltage_CMU_Num : 48|8@1+ (1,0) [0|255] "" Vector__XXX
SG_ BMS_Max_Voltage_CMU_Cell_Num : 56|8@1+ (1,0) [0|255] "" Vector__XXX

BO_ 1529 BMS_Min_Max_Cell_Temperature: 8 Vector__XXX
SG_ BMS_Min_Cell_Temp : 0|16@1+ (1,0) [0|65535] "1/10 C" Vector__XXX
SG_ BMS_Max_Cell_Temp : 16|16@1+ (1,0) [0|65535] "1/10 C" Vector__XXX
SG_ BMS_Min_Temp_CMU_Num : 32|8@1+ (1,0) [0|255] "" Vector__XXX
SG_ BMS_Unused_1 : 40|8@1+ (1,0) [0|255] "" Vector__XXX
SG_ BMS_Max_Temp_CMU_Num : 48|8@1+ (1,0) [0|255] "" Vector__XXX
SG_ BMS_Unused_2 : 56|8@1+ (1,0) [0|255] "" Vector__XXX

BO_ 1530 BMS_Pack_Voltage_Current: 8 Vector__XXX
SG_ BMS_Battery_Voltage : 0|32@1+ (1,0) [0|4294967295] "V" Vector__XXX
SG_ BMS_Battery_Current : 32|32@1+ (1,0) [0|4294967295] "mA" Vector__XXX

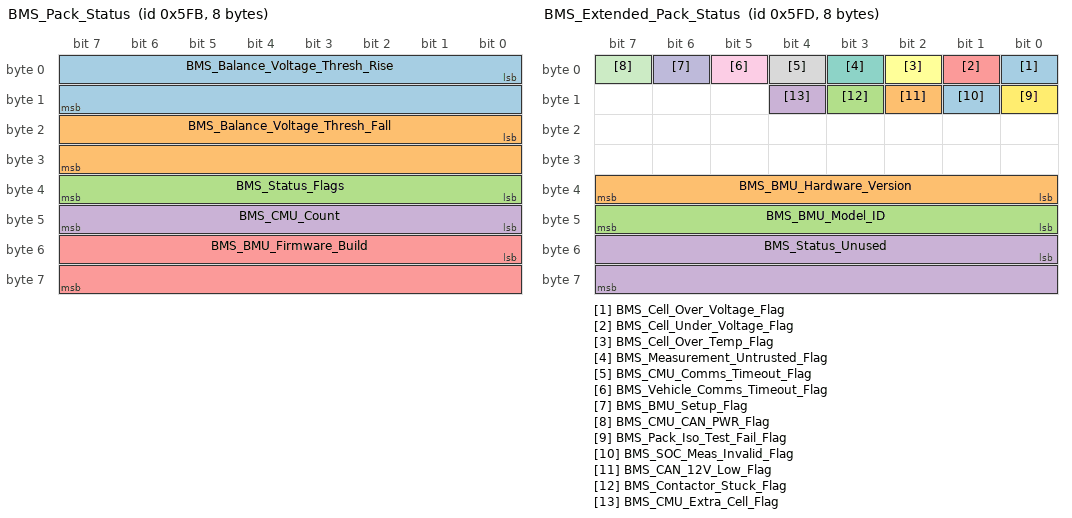
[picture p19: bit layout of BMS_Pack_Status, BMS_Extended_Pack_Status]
BO_ 1531 BMS_Pack_Status: 8 Vector__XXX
SG_ BMS_Balance_Voltage_Thresh_Rise : 0|16@1+ (1,0) [0|65535] "" Vector__XXX
SG_ BMS_Balance_Voltage_Thresh_Fall : 16|16@1+ (1,0) [0|65535] "" Vector__XXX
SG_ BMS_Status_Flags : 32|8@1+ (1,0) [0|255] "" Vector__XXX
SG_ BMS_CMU_Count : 40|8@1+ (1,0) [0|255] "" Vector__XXX
SG_ BMS_BMU_Firmware_Build : 48|16@1+ (1,0) [0|65535] "" Vector__XXX

BO_ 1532 BMS_Fan_12V_Status: 8 Vector__XXX
SG_ BMS_Fan_Speed_0 : 0|16@1+ (1,0) [0|65535] "RPM" Vector__XXX
SG_ BMS_Fan_Speed_1 : 16|16@1+ (1,0) [0|65535] "RPM" Vector__XXX
SG_ BMS_12V_Fan_Contactor_Current : 32|16@1+ (1,0) [0|65535] "mA" Vector__XXX
SG_ BMS_12V_CMU_Current : 48|16@1+ (1,0) [0|65535] "mA" Vector__XXX

BO_ 1533 BMS_Extended_Pack_Status: 8 Vector__XXX
SG_ BMS_Cell_Over_Voltage_Flag : 0|1@1+ (1,0) [0|1] "" Vector__XXX
SG_ BMS_BMU_Hardware_Version : 32|8@1+ (1,0) [0|255] "" Vector__XXX
SG_ BMS_BMU_Model_ID : 40|8@1+ (1,0) [0|255] "" Vector__XXX
SG_ BMS_Status_Unused : 48|16@1+ (1,0) [0|65535] "" Vector__XXX
SG_ BMS_Cell_Under_Voltage_Flag : 1|1@1+ (1,0) [0|1] "" Vector__XXX
SG_ BMS_Cell_Over_Temp_Flag : 2|1@1+ (1,0) [0|1] "" Vector__XXX
SG_ BMS_Measurement_Untrusted_Flag : 3|1@1+ (1,0) [0|1] "" Vector__XXX
SG_ BMS_CMU_Comms_Timeout_Flag : 4|1@1+ (1,0) [0|1] "" Vector__XXX
SG_ BMS_Vehicle_Comms_Timeout_Flag : 5|1@1+ (1,0) [0|1] "" Vector__XXX
SG_ BMS_BMU_Setup_Flag : 6|1@1+ (1,0) [0|1] "" Vector__XXX
SG_ BMS_CMU_CAN_PWR_Flag : 7|1@1+ (1,0) [0|1] "" Vector__XXX
SG_ BMS_Pack_Iso_Test_Fail_Flag : 8|1@1+ (1,0) [0|1] "" Vector__XXX
SG_ BMS_SOC_Meas_Invalid_Flag : 9|1@1+ (1,0) [0|1] "" Vector__XXX
SG_ BMS_CAN_12V_Low_Flag : 10|1@1+ (1,0) [0|1] "" Vector__XXX
SG_ BMS_Contactor_Stuck_Flag : 11|1@1+ (1,0) [0|1] "" Vector__XXX
SG_ BMS_CMU_Extra_Cell_Flag : 12|1@1+ (1,0) [0|1] "" Vector__XXX

BO_ 2032 BMS_Bootloader_1: 8 Vector__XXX

BO_ 2033 BMS_Bootloader_2: 8 Vector__XXX

BO_ 2034 BMS_Bootloader_3: 8 Vector__XXX

BO_ 2035 BMS_Bootloader_4: 8 Vector__XXX

BO_ 2036 BMS_Bootloader_5: 8 Vector__XXX

BO_ 1281 BMS_CMU_1_Status: 8 Vector__XXX
SG_ BMS_CMU_1_SN : 0|32@1+ (1,0) [0|4294967295] "" Vector__XXX
SG_ BMS_CMU_1_PCB_Temp : 32|16@1+ (1,0) [0|65535] "" Vector__XXX
SG_ BMS_CMU_1_Cell_Temp : 48|16@1+ (1,0) [0|65535] "" Vector__XXX

BO_ 1282 BMS_CMU_1_Low_Cells: 8 Vector__XXX
SG_ BMS_CMU_1_Cell_L0_Voltage : 0|16@1+ (1,0) [0|65535] "mV" Vector__XXX
SG_ BMS_CMU_1_Cell_L1_Voltage : 16|16@1+ (1,0) [0|65535] "mV" Vector__XXX
SG_ BMS_CMU_1_Cell_L2_Voltage : 32|16@1+ (1,0) [0|65535] "mV" Vector__XXX
SG_ BMS_CMU_1_Cell_L3_Voltage : 48|16@1+ (1,0) [0|65535] "mV" Vector__XXX

BO_ 1283 BMS_CMU_1_High_Cells: 8 Vector__XXX
SG_ BMS_CMU_1_Cell_H0_Voltage : 0|16@1+ (1,0) [0|65535] "" Vector__XXX
SG_ BMS_CMU_1_Cell_H1_Voltage : 16|16@1+ (1,0) [0|65535] "mV" Vector__XXX
SG_ BMS_CMU_1_Cell_H2_Voltage : 32|16@1+ (1,0) [0|65535] "mV" Vector__XXX
SG_ BMS_CMU_1_Cell_H3_Voltage : 48|16@1+ (1,0) [0|65535] "mV" Vector__XXX

BO_ 1284 BMS_CMU_2_Status: 8 Vector__XXX
SG_ BMS_CMU_2_SN : 0|32@1+ (1,0) [0|4294967295] "" Vector__XXX
SG_ BMS_CMU_2_PCB_Temp : 32|16@1+ (1,0) [0|65535] "" Vector__XXX
SG_ BMS_CMU_2_Cell_Temp : 48|16@1+ (1,0) [0|65535] "" Vector__XXX

BO_ 1285 BMS_CMU_2_Low_Cells: 8 Vector__XXX
SG_ BMS_CMU_2_Cell_L0_Voltage : 0|16@1+ (1,0) [0|65535] "mV" Vector__XXX
SG_ BMS_CMU_2_Cell_L1_Voltage : 16|16@1+ (1,0) [0|65535] "mV" Vector__XXX
SG_ BMS_CMU_2_Cell_L2_Voltage : 32|16@1+ (1,0) [0|65535] "mV" Vector__XXX
SG_ BMS_CMU_2_Cell_L3_Voltage : 48|16@1+ (1,0) [0|65535] "mV" Vector__XXX

BO_ 1286 BMS_CMU_2_High_Cells: 8 Vector__XXX
SG_ BMS_CMU_2_Cell_H0_Voltage : 0|16@1+ (1,0) [0|65535] "" Vector__XXX
SG_ BMS_CMU_2_Cell_H1_Voltage : 16|16@1+ (1,0) [0|65535] "mV" Vector__XXX
SG_ BMS_CMU_2_Cell_H2_Voltage : 32|16@1+ (1,0) [0|65535] "mV" Vector__XXX
SG_ BMS_CMU_2_Cell_H3_Voltage : 48|16@1+ (1,0) [0|65535] "mV" Vector__XXX

BO_ 1287 BMS_CMU_3_Status: 8 Vector__XXX
SG_ BMS_CMU_3_SN : 0|32@1+ (1,0) [0|4294967295] "" Vector__XXX
SG_ BMS_CMU_3_PCB_Temp : 32|16@1+ (1,0) [0|65535] "" Vector__XXX
SG_ BMS_CMU_3_Cell_Temp : 48|16@1+ (1,0) [0|65535] "" Vector__XXX

BO_ 1290 BMS_CMU_4_Status: 8 Vector__XXX
SG_ BMS_CMU_4_SN : 0|32@1+ (1,0) [0|4294967295] "" Vector__XXX
SG_ BMS_CMU_4_PCB_Temp : 32|16@1+ (1,0) [0|65535] "" Vector__XXX
SG_ BMS_CMU_4_Cell_Temp : 48|16@1+ (1,0) [0|65535] "" Vector__XXX

BO_ 1293 BMS_CMU_5_Status: 8 Vector__XXX
SG_ BMS_CMU_5_SN : 0|32@1+ (1,0) [0|4294967295] "" Vector__XXX
SG_ BMS_CMU_5_PCB_Temp : 32|16@1+ (1,0) [0|65535] "" Vector__XXX
SG_ BMS_CMU_5_Cell_Temp : 48|16@1+ (1,0) [0|65535] "" Vector__XXX

BO_ 1296 BMS_CMU_6_Status: 8 Vector__XXX
SG_ BMS_CMU_6_SN : 0|32@1+ (1,0) [0|4294967295] "" Vector__XXX
SG_ BMS_CMU_6_PCB_Temp : 32|16@1+ (1,0) [0|65535] "" Vector__XXX
SG_ BMS_CMU_6_Cell_Temp : 48|16@1+ (1,0) [0|65535] "" Vector__XXX

BO_ 1299 BMS_CMU_7_Status: 8 Vector__XXX
SG_ BMS_CMU_7_SN : 0|32@1+ (1,0) [0|4294967295] "" Vector__XXX
SG_ BMS_CMU_7_PCB_Temp : 32|16@1+ (1,0) [0|65535] "" Vector__XXX
SG_ BMS_CMU_7_Cell_Temp : 48|16@1+ (1,0) [0|65535] "" Vector__XXX

BO_ 1302 BMS_CMU_8_Status: 8 Vector__XXX
SG_ BMS_CMU_8_SN : 0|32@1+ (1,0) [0|4294967295] "" Vector__XXX
SG_ BMS_CMU_8_PCB_Temp : 32|16@1+ (1,0) [0|65535] "" Vector__XXX
SG_ BMS_CMU_8_Cell_Temp : 48|16@1+ (1,0) [0|65535] "" Vector__XXX

BO_ 1305 BMS_CMU_9_Status: 8 Vector__XXX
SG_ BMS_CMU_9_SN : 0|32@1+ (1,0) [0|4294967295] "" Vector__XXX
SG_ BMS_CMU_9_PCB_Temp : 32|16@1+ (1,0) [0|65535] "" Vector__XXX
SG_ BMS_CMU_9_Cell_Temp : 48|16@1+ (1,0) [0|65535] "" Vector__XXX

BO_ 1308 BMS_CMU_10_Status: 8 Vector__XXX
SG_ BMS_CMU_10_SN : 0|32@1+ (1,0) [0|4294967295] "" Vector__XXX
SG_ BMS_CMU_10_PCB_Temp : 32|16@1+ (1,0) [0|65535] "" Vector__XXX
SG_ BMS_CMU_10_Cell_Temp : 48|16@1+ (1,0) [0|65535] "" Vector__XXX

BO_ 1311 BMS_CMU_11_Status: 8 Vector__XXX
SG_ BMS_CMU_11_SN : 0|32@1+ (1,0) [0|4294967295] "" Vector__XXX
SG_ BMS_CMU_11_PCB_Temp : 32|16@1+ (1,0) [0|65535] "" Vector__XXX
SG_ BMS_CMU_11_Cell_Temp : 48|16@1+ (1,0) [0|65535] "" Vector__XXX

BO_ 1314 BMS_CMU_12_Status: 8 Vector__XXX
SG_ BMS_CMU_12_SN : 0|32@1+ (1,0) [0|4294967295] "" Vector__XXX
SG_ BMS_CMU_12_PCB_Temp : 32|16@1+ (1,0) [0|65535] "" Vector__XXX
SG_ BMS_CMU_12_Cell_Temp : 48|16@1+ (1,0) [0|65535] "" Vector__XXX

BO_ 1288 BMS_CMU_3_Low_Cells: 8 Vector__XXX
SG_ BMS_CMU_3_Cell_L0_Voltage : 0|16@1+ (1,0) [0|65535] "mV" Vector__XXX
SG_ BMS_CMU_3_Cell_L1_Voltage : 16|16@1+ (1,0) [0|65535] "mV" Vector__XXX
SG_ BMS_CMU_3_Cell_L2_Voltage : 32|16@1+ (1,0) [0|65535] "mV" Vector__XXX
SG_ BMS_CMU_3_Cell_L3_Voltage : 48|16@1+ (1,0) [0|65535] "mV" Vector__XXX

BO_ 1291 BMS_CMU_4_Low_Cells: 8 Vector__XXX
SG_ BMS_CMU_4_Cell_L0_Voltage : 0|16@1+ (1,0) [0|65535] "mV" Vector__XXX
SG_ BMS_CMU_4_Cell_L1_Voltage : 16|16@1+ (1,0) [0|65535] "mV" Vector__XXX
SG_ BMS_CMU_4_Cell_L2_Voltage : 32|16@1+ (1,0) [0|65535] "mV" Vector__XXX
SG_ BMS_CMU_4_Cell_L3_Voltage : 48|16@1+ (1,0) [0|65535] "mV" Vector__XXX

BO_ 1294 BMS_CMU_5_Low_Cells: 8 Vector__XXX
SG_ BMS_CMU_5_Cell_L0_Voltage : 0|16@1+ (1,0) [0|65535] "mV" Vector__XXX
SG_ BMS_CMU_5_Cell_L1_Voltage : 16|16@1+ (1,0) [0|65535] "mV" Vector__XXX
SG_ BMS_CMU_5_Cell_L2_Voltage : 32|16@1+ (1,0) [0|65535] "mV" Vector__XXX
SG_ BMS_CMU_5_Cell_L3_Voltage : 48|16@1+ (1,0) [0|65535] "mV" Vector__XXX

BO_ 1297 BMS_CMU_6_Low_Cells: 8 Vector__XXX
SG_ BMS_CMU_6_Cell_L0_Voltage : 0|16@1+ (1,0) [0|65535] "mV" Vector__XXX
SG_ BMS_CMU_6_Cell_L1_Voltage : 16|16@1+ (1,0) [0|65535] "mV" Vector__XXX
SG_ BMS_CMU_6_Cell_L2_Voltage : 32|16@1+ (1,0) [0|65535] "mV" Vector__XXX
SG_ BMS_CMU_6_Cell_L3_Voltage : 48|16@1+ (1,0) [0|65535] "mV" Vector__XXX

BO_ 1300 BMS_CMU_7_Low_Cells: 8 Vector__XXX
SG_ BMS_CMU_7_Cell_L0_Voltage : 0|16@1+ (1,0) [0|65535] "mV" Vector__XXX
SG_ BMS_CMU_7_Cell_L1_Voltage : 16|16@1+ (1,0) [0|65535] "mV" Vector__XXX
SG_ BMS_CMU_7_Cell_L2_Voltage : 32|16@1+ (1,0) [0|65535] "mV" Vector__XXX
SG_ BMS_CMU_7_Cell_L3_Voltage : 48|16@1+ (1,0) [0|65535] "mV" Vector__XXX

BO_ 1303 BMS_CMU_8_Low_Cells: 8 Vector__XXX
SG_ BMS_CMU_8_Cell_L0_Voltage : 0|16@1+ (1,0) [0|65535] "mV" Vector__XXX
SG_ BMS_CMU_8_Cell_L1_Voltage : 16|16@1+ (1,0) [0|65535] "mV" Vector__XXX
SG_ BMS_CMU_8_Cell_L2_Voltage : 32|16@1+ (1,0) [0|65535] "mV" Vector__XXX
SG_ BMS_CMU_8_Cell_L3_Voltage : 48|16@1+ (1,0) [0|65535] "mV" Vector__XXX

BO_ 1306 BMS_CMU_9_Low_Cells: 8 Vector__XXX
SG_ BMS_CMU_9_Cell_L0_Voltage : 0|16@1+ (1,0) [0|65535] "mV" Vector__XXX
SG_ BMS_CMU_9_Cell_L1_Voltage : 16|16@1+ (1,0) [0|65535] "mV" Vector__XXX
SG_ BMS_CMU_9_Cell_L2_Voltage : 32|16@1+ (1,0) [0|65535] "mV" Vector__XXX
SG_ BMS_CMU_9_Cell_L3_Voltage : 48|16@1+ (1,0) [0|65535] "mV" Vector__XXX

BO_ 1309 BMS_CMU_10_Low_Cells: 8 Vector__XXX
SG_ BMS_CMU_10_Cell_L0_Voltage : 0|16@1+ (1,0) [0|65535] "mV" Vector__XXX
SG_ BMS_CMU_10_Cell_L1_Voltage : 16|16@1+ (1,0) [0|65535] "mV" Vector__XXX
SG_ BMS_CMU_10_Cell_L2_Voltage : 32|16@1+ (1,0) [0|65535] "mV" Vector__XXX
SG_ BMS_CMU_10_Cell_L3_Voltage : 48|16@1+ (1,0) [0|65535] "mV" Vector__XXX

BO_ 1312 BMS_CMU_11_Low_Cells: 8 Vector__XXX
SG_ BMS_CMU_11_Cell_L0_Voltage : 0|16@1+ (1,0) [0|65535] "mV" Vector__XXX
SG_ BMS_CMU_11_Cell_L1_Voltage : 16|16@1+ (1,0) [0|65535] "mV" Vector__XXX
SG_ BMS_CMU_11_Cell_L2_Voltage : 32|16@1+ (1,0) [0|65535] "mV" Vector__XXX
SG_ BMS_CMU_11_Cell_L3_Voltage : 48|16@1+ (1,0) [0|65535] "mV" Vector__XXX

BO_ 1315 BMS_CMU_12_Low_Cells: 8 Vector__XXX
SG_ BMS_CMU_12_Cell_L0_Voltage : 0|16@1+ (1,0) [0|65535] "mV" Vector__XXX
SG_ BMS_CMU_12_Cell_L1_Voltage : 16|16@1+ (1,0) [0|65535] "mV" Vector__XXX
SG_ BMS_CMU_12_Cell_L2_Voltage : 32|16@1+ (1,0) [0|65535] "mV" Vector__XXX
SG_ BMS_CMU_12_Cell_L3_Voltage : 48|16@1+ (1,0) [0|65535] "mV" Vector__XXX

BO_ 1289 BMS_CMU_3_High_Cells: 8 Vector__XXX
SG_ BMS_CMU_3_Cell_H0_Voltage : 0|16@1+ (1,0) [0|65535] "mV" Vector__XXX
SG_ BMS_CMU_3_Cell_H1_Voltage : 16|16@1+ (1,0) [0|65535] "mV" Vector__XXX
SG_ BMS_CMU_3_Cell_H2_Voltage : 32|16@1+ (1,0) [0|65535] "mV" Vector__XXX
SG_ BMS_CMU_3_Cell_H3_Voltage : 48|16@1+ (1,0) [0|65535] "mV" Vector__XXX

BO_ 1292 BMS_CMU_4_High_Cells: 8 Vector__XXX
SG_ BMS_CMU_4_Cell_H0_Voltage : 0|16@1+ (1,0) [0|65535] "mV" Vector__XXX
SG_ BMS_CMU_4_Cell_H1_Voltage : 16|16@1+ (1,0) [0|65535] "mV" Vector__XXX
SG_ BMS_CMU_4_Cell_H2_Voltage : 32|16@1+ (1,0) [0|65535] "mV" Vector__XXX
SG_ BMS_CMU_4_Cell_H3_Voltage : 48|16@1+ (1,0) [0|65535] "mV" Vector__XXX

BO_ 1295 BMS_CMU_5_High_Cells: 8 Vector__XXX
SG_ BMS_CMU_5_Cell_H0_Voltage : 0|16@1+ (1,0) [0|65535] "mV" Vector__XXX
SG_ BMS_CMU_5_Cell_H1_Voltage : 16|16@1+ (1,0) [0|65535] "mV" Vector__XXX
SG_ BMS_CMU_5_Cell_H2_Voltage : 32|16@1+ (1,0) [0|65535] "mV" Vector__XXX
SG_ BMS_CMU_5_Cell_H3_Voltage : 48|16@1+ (1,0) [0|65535] "mV" Vector__XXX

BO_ 1298 BMS_CMU_6_High_Cells: 8 Vector__XXX
SG_ BMS_CMU_6_Cell_H0_Voltage : 0|16@1+ (1,0) [0|65535] "mV" Vector__XXX
SG_ BMS_CMU_6_Cell_H1_Voltage : 16|16@1+ (1,0) [0|65535] "mV" Vector__XXX
SG_ BMS_CMU_6_Cell_H2_Voltage : 32|16@1+ (1,0) [0|65535] "mV" Vector__XXX
SG_ BMS_CMU_6_Cell_H3_Voltage : 48|16@1+ (1,0) [0|65535] "mV" Vector__XXX

BO_ 1301 BMS_CMU_7_High_Cells: 8 Vector__XXX
SG_ BMS_CMU_7_Cell_H0_Voltage : 0|16@1+ (1,0) [0|65535] "mV" Vector__XXX
SG_ BMS_CMU_7_Cell_H1_Voltage : 16|16@1+ (1,0) [0|65535] "mV" Vector__XXX
SG_ BMS_CMU_7_Cell_H2_Voltage : 32|16@1+ (1,0) [0|65535] "mV" Vector__XXX
SG_ BMS_CMU_7_Cell_H3_Voltage : 48|16@1+ (1,0) [0|65535] "mV" Vector__XXX

BO_ 1304 BMS_CMU_8_High_Cells: 8 Vector__XXX
SG_ BMS_CMU_8_Cell_H0_Voltage : 0|16@1+ (1,0) [0|65535] "mV" Vector__XXX
SG_ BMS_CMU_8_Cell_H1_Voltage : 16|16@1+ (1,0) [0|65535] "mV" Vector__XXX
SG_ BMS_CMU_8_Cell_H2_Voltage : 32|16@1+ (1,0) [0|65535] "mV" Vector__XXX
SG_ BMS_CMU_8_Cell_H3_Voltage : 48|16@1+ (1,0) [0|65535] "mV" Vector__XXX

BO_ 1307 BMS_CMU_9_High_Cells: 8 Vector__XXX
SG_ BMS_CMU_9_Cell_H0_Voltage : 0|16@1+ (1,0) [0|65535] "mV" Vector__XXX
SG_ BMS_CMU_9_Cell_H1_Voltage : 16|16@1+ (1,0) [0|65535] "mV" Vector__XXX
SG_ BMS_CMU_9_Cell_H2_Voltage : 32|16@1+ (1,0) [0|65535] "mV" Vector__XXX
SG_ BMS_CMU_9_Cell_H3_Voltage : 48|16@1+ (1,0) [0|65535] "mV" Vector__XXX

BO_ 1310 BMS_CMU_10_High_Cells: 8 Vector__XXX
SG_ BMS_CMU_10_Cell_H0_Voltage : 0|16@1+ (1,0) [0|65535] "mV" Vector__XXX
SG_ BMS_CMU_10_Cell_H1_Voltage : 16|16@1+ (1,0) [0|65535] "mV" Vector__XXX
SG_ BMS_CMU_10_Cell_H2_Voltage : 32|16@1+ (1,0) [0|65535] "mV" Vector__XXX
SG_ BMS_CMU_10_Cell_H3_Voltage : 48|16@1+ (1,0) [0|65535] "mV" Vector__XXX

BO_ 1313 BMS_CMU_11_High_Cells: 8 Vector__XXX
SG_ BMS_CMU_11_Cell_H0_Voltage : 0|16@1+ (1,0) [0|65535] "mV" Vector__XXX
SG_ BMS_CMU_11_Cell_H1_Voltage : 16|16@1+ (1,0) [0|65535] "mV" Vector__XXX
SG_ BMS_CMU_11_Cell_H2_Voltage : 32|16@1+ (1,0) [0|65535] "mV" Vector__XXX
SG_ BMS_CMU_11_Cell_H3_Voltage : 48|16@1+ (1,0) [0|65535] "mV" Vector__XXX

BO_ 1316 BMS_CMU_12_High_Cells: 8 Vector__XXX
SG_ BMS_CMU_12_Cell_H0_Voltage : 0|16@1+ (1,0) [0|65535] "mV" Vector__XXX
SG_ BMS_CMU_12_Cell_H1_Voltage : 16|16@1+ (1,0) [0|65535] "mV" Vector__XXX
SG_ BMS_CMU_12_Cell_H2_Voltage : 32|16@1+ (1,0) [0|65535] "mV" Vector__XXX
SG_ BMS_CMU_12_Cell_H3_Voltage : 48|16@1+ (1,0) [0|65535] "mV" Vector__XXX

BO_ 1791 LED_Brightness: 1 Vector__XXX
SG_ LED_Brightness : 0|8@1+ (1,0) [0|255] "" Vector__XXX

BO_ 1541 BMS_Drive_Control: 8 Vector__XXX
SG_ BMS_Ignition_Switch : 0|16@1+ (1,0) [0|65535] "" Vector__XXX
SG_ BMS_Unused_1 : 16|16@1+ (1,0) [0|65535] "" Vector__XXX
SG_ BMS_Unused_2 : 32|16@1+ (1,0) [0|65535] "" Vector__XXX
SG_ BMS_Unused_3 : 48|16@1+ (1,0) [0|65535] "" Vector__XXX

CM_ BO_ 514 "Front Sensor Module Heartbeat";
CM_ SG_ 514 FSM_State "Current Module State";
CM_ BO_ 516 "Driver Interface Module Hearbeat";
CM_ BO_ 519 "Comms Module Heartbeat";
CM_ SG_ 519 Comms_State "Current Module State";
CM_ BO_ 528 "CMRduino Heartbeat";
CM_ SG_ 528 Comms_State "Current Module State";
CM_ SG_ 941 MC_L_Iq_Command "The commanded Q-axis current";
CM_ SG_ 941 MC_L_Id_Command "The commanded D-axis current";
CM_ SG_ 941 MC_L_Flux_Weakening_Output "This is the current output of the flux regulator.";
CM_ SG_ 941 MC_L_Modulation_Index "This is the modulation index. The scale factor is x100. To get the actual modulation index divide the value by 100.";
CM_ SG_ 940 MC_L_Power_On_Timer "Updated every 3 msec. This will roll over in approximately 150 days!";
CM_ SG_ 940 MC_L_Torque_Feedback "Estimated motor torque feedback";
CM_ SG_ 940 MC_L_Commanded_Torque "The commanded Torque";
CM_ BO_ 962 "To write a parameter use message 0x0C1 with byte #2 set to 1 (write). To read a parameter use message 0x0C1 with byte #2 to set 0 (read). ";
CM_ SG_ 962 MC_L_Write_Success "0=Write failure, 1=Success";
CM_ SG_ 962 MC_L_Data_Response "All EEPROM data is 16 bits and is contained in bytes 4 and 5. Bytes 6 and 7 should be ignored.";
CM_ SG_ 962 MC_L_Parameter_Address_Response "Valid EEPROM Parameter CAN addresses are between 100 and 499.";
CM_ BO_ 961 "To write a parameter use message 0x0C1 with byte #2 set to 1 (write). To read a parameter use message 0x0C1 with byte #2 to set 0 (read). ";
CM_ SG_ 961 MC_L_Data_Command "All EEPROM data is 16 bits and is contained in bytes 4 and 5.";
CM_ SG_ 961 MC_L_Read_Write_Command "0=Read, 1=Write";
CM_ SG_ 961 MC_L_Parameter_Address_Command "Valid EEPROM Parameter CAN addresses are between 100 and 499.";
CM_ BO_ 960 "The command message is used to transmit data to the controller. This message is sent from a user supplied external controller to the PMxxx controller.";
CM_ SG_ 960 MC_L_Inverter_Enable "0=Inverter OFF, 1 = Inverter ON";
CM_ SG_ 960 MC_L_Direction_Command "0=CW, 1=CCW as veiwed from the shaft end of the motor";
CM_ SG_ 960 MC_L_Speed_Command "Speed commandused when in speed mode";
CM_ SG_ 960 MC_L_Torque_Command "Torque command when in torque mode";
CM_ SG_ 960 MC_L_Inverter_Discharge "0=Discharge Disable,=Discharge Enable";
CM_ SG_ 960 MC_L_Torque_Limit_Command "Torque Limit, set to 0 to keep default";
CM_ SG_ 960 MC_L_Speed_Mode_Enable "0 = No change to mode, 1 = change to speed mode from torque mode";
CM_ SG_ 939 MC_L_Run_Fault_Hi "Each bit represents a fault. Please refer to PM100 Users Manual for details.";
CM_ SG_ 939 MC_L_Post_Fault_Hi "Each bit represents a fault. Please refer to PM100 Users Manual for details.";
CM_ SG_ 939 MC_L_Run_Fault_Lo "Each bit represents a fault. Please refer to PM100 Users Manual for details.";
CM_ SG_ 939 MC_L_Post_Fault_Lo "Each bit represents a fault. Please refer to PM100 Users Manual for details.";
CM_ SG_ 938 MC_L_Direction_Command "1 = Forward0 = 'Reverse' if inverter enabled  & 'Stopped' if inverter is disabled";
CM_ SG_ 938 MC_L_Inverter_Enable_State "0=Inverter Disabled, 1=Inverter Enabled";
CM_ SG_ 938 MC_L_Relay_3_Status "0=OFF, 1=ON";
CM_ SG_ 938 MC_L_Relay_4_Status "0=OFF, 1=ON";
CM_ SG_ 938 MC_L_Relay_2_Status "0=OFF, 1=ON";
CM_ SG_ 938 MC_L_Inverter_Run_Mode "0=Torque Mode, 1=Speed Mode";
CM_ SG_ 938 MC_L_Inverter_Command_Mode "0=CAN mode, 1=VSM mode";
CM_ SG_ 938 MC_L_Relay_1_Status "0=OFF, 1=ON";
CM_ SG_ 938 MC_L_Inverter_State "Different states for the inverter state machine";
CM_ SG_ 938 MC_L_VSM_State "Different states for the vehicle state machine";
CM_ SG_ 938 MC_L_Inverter_Enable_Lockout "0=Lockout Disabled, 1=Lockout Enabled";
CM_ SG_ 938 MC_L_Inverter_Discharge_State "0 = Disabled, 1 = Enabled, 2 = Speed Check, 3 = Active, 4 = Complete";
CM_ SG_ 938 MC_L_Relay_5_Status "0=OFF, 1=ON";
CM_ SG_ 938 MC_L_Relay_6_Status "0=OFF, 1=ON";
CM_ SG_ 937 MC_L_Reference_Voltage_12_0 "12V Input Voltage";
CM_ SG_ 937 MC_L_Reference_Voltage_5_0 "Transducer voltage";
CM_ SG_ 937 MC_L_Reference_Voltage_2_5 "Internal reference voltage";
CM_ SG_ 937 MC_L_Reference_Voltage_1_5 "Internal reference voltage";
CM_ SG_ 936 MC_L_Iq "The measured Iq current";
CM_ SG_ 936 MC_L_Id "The measured Id current";
CM_ SG_ 936 MC_L_Flux_Feedback "The estimated flux";
CM_ SG_ 936 MC_L_Flux_Command "The commanded flux";
CM_ SG_ 935 MC_L_Phase_BC_Voltage "Measured value of the voltage between Phase B and Phase C";
CM_ SG_ 935 MC_L_Phase_AB_Voltage "Measured value of the voltage betwen phase A and Phase B";
CM_ SG_ 935 MC_L_Output_Voltage "The calculated value of the output voltage, in peak line-neutral volts";
CM_ SG_ 935 MC_L_DC_Bus_Voltage "The actual measured value of the DC bus voltage";
CM_ SG_ 934 MC_L_DC_Bus_Current "The Calculated DC Bus Current";
CM_ SG_ 934 MC_L_Phase_C_Current "The measured value of Phase C current";
CM_ SG_ 934 MC_L_Phase_B_Current "The measured value of Phase B current";
CM_ SG_ 934 MC_L_Phase_A_Current "The measured value of Phase A current";
CM_ SG_ 933 MC_L_Delta_Resolver_Filtered "Used in calibration of resolver angle adjustment.";
CM_ SG_ 933 MC_L_Electrical_Output_Frequency "The actual electrical frequency of the inverter";
CM_ SG_ 933 MC_L_Motor_Speed "The measured speed of the motor";
CM_ SG_ 933 MC_L_Motor_Angle_Electrical "The Electrical Angle of the motor as read by the encoder or resolver";
CM_ SG_ 932 MC_L_Digital_Input_5 "Status of Digital Input #5";
CM_ SG_ 932 MC_L_Digital_Input_4 "Status of Digital Input #4";
CM_ SG_ 932 MC_L_Digital_Input_3 "Status of Digital Input #3";
CM_ SG_ 932 MC_L_Digital_Input_2 "Status of Digital Input #2";
CM_ SG_ 932 MC_L_Digital_Input_1 "Status of Digital Input #1";
CM_ SG_ 932 MC_L_Digital_Input_6 "Status of Digital Input #6";
CM_ SG_ 932 MC_L_Digital_Input_7 "Status of Digital Input #7";
CM_ SG_ 932 MC_L_Digital_Input_8 "Status of Digital Input #8";
CM_ SG_ 931 MC_L_Analog_Input_4_Voltage "Voltage on Analog Input #4";
CM_ SG_ 931 MC_L_Analog_Input_3_Voltage "Voltage on Analog Input #3";
CM_ SG_ 931 MC_L_Analog_Input_2_Voltage "Voltage on Analog Input #2";
CM_ SG_ 931 MC_L_Analog_Input_1_Voltage "Voltage on Analog Input #1";
CM_ SG_ 930 MC_L_Torque_Shudder "Shudder compensation value of torque";
CM_ SG_ 930 MC_L_Motor_Temp "Motor Temperature Sensor";
CM_ SG_ 930 MC_L_RTD5_Temp "RTD 5 (PT1000) Temperature";
CM_ SG_ 930 MC_L_RTD4_Temp "RTD 4 (PT1000) Temperature";
CM_ SG_ 929 MC_L_RTD3_Temp "RTD input 3 (PT1000) Temperature";
CM_ SG_ 929 MC_L_RTD2_Temp "RTD input 2 (PT1000) Temperature";
CM_ SG_ 929 MC_L_RTD1_Temp "RTD input 1 (PT1000) Temperature";
CM_ SG_ 929 MC_L_Control_Board_Temp "Control Board Temperature";
CM_ SG_ 928 MC_L_Gate_Driver_Board_Temp "Gate Driver Board Temperature";
CM_ SG_ 928 MC_L_Module_C_Temp "IGBT Module C Temperature";
CM_ SG_ 928 MC_L_Module_B_Temp "IGBT Module B Temperature";
CM_ SG_ 928 MC_L_Module_A_Temp "IGBT Module A Temperature";
CM_ SG_ 1197 MC_R_Iq_Command "The commanded Q-axis current";
CM_ SG_ 1197 MC_R_Id_Command "The commanded D-axis current";
CM_ SG_ 1197 MC_R_Flux_Weakening_Output "This is the current output of the flux regulator.";
CM_ SG_ 1197 MC_R_Modulation_Index "This is the modulation index. The scale factor is x100. To get the actual modulation index divide the value by 100.";
CM_ SG_ 1196 MC_R_Power_On_Timer "Updated every 3 msec. This will roll over in approximately 150 days!";
CM_ SG_ 1196 MC_R_Torque_Feedback "Estimated motor torque feedback";
CM_ SG_ 1196 MC_R_Commanded_Torque "The commanded Torque";
CM_ BO_ 1218 "To write a parameter use message 0x0C1 with byte #2 set to 1 (write). To read a parameter use message 0x0C1 with byte #2 to set 0 (read). ";
CM_ SG_ 1218 MC_R_Write_Success "0=Write failure, 1=Success";
CM_ SG_ 1218 MC_R_Data_Response "All EEPROM data is 16 bits and is contained in bytes 4 and 5. Bytes 6 and 7 should be ignored.";
CM_ SG_ 1218 MC_R_Parameter_Address_Response "Valid EEPROM Parameter CAN addresses are between 100 and 499.";
CM_ BO_ 1217 "To write a parameter use message 0x0C1 with byte #2 set to 1 (write). To read a parameter use message 0x0C1 with byte #2 to set 0 (read). ";
CM_ SG_ 1217 MC_R_Data_Command "All EEPROM data is 16 bits and is contained in bytes 4 and 5.";
CM_ SG_ 1217 MC_R_Read_Write_Command "0=Read, 1=Write";
CM_ SG_ 1217 MC_R_Parameter_Address_Command "Valid EEPROM Parameter CAN addresses are between 100 and 499.";
CM_ BO_ 1216 "The command message is used to transmit data to the controller. This message is sent from a user supplied external controller to the PMxxx controller.";
CM_ SG_ 1216 MC_R_Inverter_Enable "0=Inverter OFF, 1 = Inverter ON";
CM_ SG_ 1216 MC_R_Direction_Command "0=CW, 1=CCW as veiwed from the shaft end of the motor";
CM_ SG_ 1216 MC_R_Speed_Command "Speed commandused when in speed mode";
CM_ SG_ 1216 MC_R_Torque_Command "Torque command when in torque mode";
CM_ SG_ 1216 MC_R_Inverter_Discharge "0=Discharge Disable,=Discharge Enable";
CM_ SG_ 1216 MC_R_Torque_Limit_Command "Torque Limit, set to 0 to keep default";
CM_ SG_ 1216 MC_R_Speed_Mode_Enable "0 = No change to mode, 1 = change to speed mode from torque mode";
CM_ SG_ 1195 MC_R_Run_Fault_Hi "Each bit represents a fault. Please refer to PM100 Users Manual for details.";
CM_ SG_ 1195 MC_R_Post_Fault_Hi "Each bit represents a fault. Please refer to PM100 Users Manual for details.";
CM_ SG_ 1195 MC_R_Run_Fault_Lo "Each bit represents a fault. Please refer to PM100 Users Manual for details.";
CM_ SG_ 1195 MC_R_Post_Fault_Lo "Each bit represents a fault. Please refer to PM100 Users Manual for details.";
CM_ SG_ 1194 MC_R_Direction_Command "1 = Forward0 = 'Reverse' if inverter enabled  & 'Stopped' if inverter is disabled";
CM_ SG_ 1194 MC_R_Inverter_Enable_State "0=Inverter Disabled, 1=Inverter Enabled";
CM_ SG_ 1194 MC_R_Relay_3_Status "0=OFF, 1=ON";
CM_ SG_ 1194 MC_R_Relay_4_Status "0=OFF, 1=ON";
CM_ SG_ 1194 MC_R_Relay_2_Status "0=OFF, 1=ON";
CM_ SG_ 1194 MC_R_Inverter_Run_Mode "0=Torque Mode, 1=Speed Mode";
CM_ SG_ 1194 MC_R_Inverter_Command_Mode "0=CAN mode, 1=VSM mode";
CM_ SG_ 1194 MC_R_Relay_1_Status "0=OFF, 1=ON";
CM_ SG_ 1194 MC_R_Inverter_State "Different states for the inverter state machine";
CM_ SG_ 1194 MC_R_VSM_State "Different states for the vehicle state machine";
CM_ SG_ 1194 MC_R_Inverter_Enable_Lockout "0=Lockout Disabled, 1=Lockout Enabled";
CM_ SG_ 1194 MC_R_Inverter_Discharge_State "0 = Disabled, 1 = Enabled, 2 = Speed Check, 3 = Active, 4 = Complete";
CM_ SG_ 1194 MC_R_Relay_5_Status "0=OFF, 1=ON";
CM_ SG_ 1194 MC_R_Relay_6_Status "0=OFF, 1=ON";
CM_ SG_ 1193 MC_R_Reference_Voltage_12_0 "12V Input Voltage";
CM_ SG_ 1193 MC_R_Reference_Voltage_5_0 "Transducer voltage";
CM_ SG_ 1193 MC_R_Reference_Voltage_2_5 "Internal reference voltage";
CM_ SG_ 1193 MC_R_Reference_Voltage_1_5 "Internal reference voltage";
CM_ SG_ 1192 MC_R_Iq "The measured Iq current";
CM_ SG_ 1192 MC_R_Id "The measured Id current";
CM_ SG_ 1192 MC_R_Flux_Feedback "The estimated flux";
CM_ SG_ 1192 MC_R_Flux_Command "The commanded flux";
CM_ SG_ 1191 MC_R_Phase_BC_Voltage "Measured value of the voltage between Phase B and Phase C";
CM_ SG_ 1191 MC_R_Phase_AB_Voltage "Measured value of the voltage betwen phase A and Phase B";
CM_ SG_ 1191 MC_R_Output_Voltage "The calculated value of the output voltage, in peak line-neutral volts";
CM_ SG_ 1191 MC_R_DC_Bus_Voltage "The actual measured value of the DC bus voltage";
CM_ SG_ 1190 MC_R_DC_Bus_Current "The Calculated DC Bus Current";
CM_ SG_ 1190 MC_R_Phase_C_Current "The measured value of Phase C current";
CM_ SG_ 1190 MC_R_Phase_B_Current "The measured value of Phase B current";
CM_ SG_ 1190 MC_R_Phase_A_Current "The measured value of Phase A current";
CM_ SG_ 1189 MC_R_Delta_Resolver_Filtered "Used in calibration of resolver angle adjustment.";
CM_ SG_ 1189 MC_R_Electrical_Output_Frequency "The actual electrical frequency of the inverter";
CM_ SG_ 1189 MC_R_Motor_Speed "The measured speed of the motor";
CM_ SG_ 1189 MC_R_Motor_Angle_Electrical "The Electrical Angle of the motor as read by the encoder or resolver";
CM_ SG_ 1188 MC_R_Digital_Input_5 "Status of Digital Input #5";
CM_ SG_ 1188 MC_R_Digital_Input_4 "Status of Digital Input #4";
CM_ SG_ 1188 MC_R_Digital_Input_3 "Status of Digital Input #3";
CM_ SG_ 1188 MC_R_Digital_Input_2 "Status of Digital Input #2";
CM_ SG_ 1188 MC_R_Digital_Input_1 "Status of Digital Input #1";
CM_ SG_ 1188 MC_R_Digital_Input_6 "Status of Digital Input #6";
CM_ SG_ 1188 MC_R_Digital_Input_7 "Status of Digital Input #7";
CM_ SG_ 1188 MC_R_Digital_Input_8 "Status of Digital Input #8";
CM_ SG_ 1187 MC_R_Analog_Input_4 "Voltage on Analog Input #4";
CM_ SG_ 1187 MC_R_Analog_Input_3 "Voltage on Analog Input #3";
CM_ SG_ 1187 MC_R_Analog_Input_2 "Voltage on Analog Input #2";
CM_ SG_ 1187 MC_R_Analog_Input_1 "Voltage on Analog Input #1";
CM_ SG_ 1186 MC_R_Torque_Shudder "Shudder compensation value of torque";
CM_ SG_ 1186 MC_R_Motor_Temp "Motor Temperature Sensor";
CM_ SG_ 1186 MC_R_RTD5_Temp "RTD 5 (PT1000) Temperature";
CM_ SG_ 1186 MC_R_RTD4_Temp "RTD 4 (PT1000) Temperature";
CM_ SG_ 1185 MC_R_RTD3_Temp "RTD input 3 (PT1000) Temperature";
CM_ SG_ 1185 MC_R_RTD2_Temp "RTD input 2 (PT1000) Temperature";
CM_ SG_ 1185 MC_R_RTD1_Temp "RTD input 1 (PT1000) Temperature";
CM_ SG_ 1185 MC_R_Control_Board_Temp "Control Board Temperature";
CM_ SG_ 1184 MC_R_Gate_Driver_Board_Temp "Gate Driver Board Temperature";
CM_ SG_ 1184 MC_R_Module_C_Temp "IGBT Module C Temperature";
CM_ SG_ 1184 MC_R_Module_B_Temp "IGBT Module B Temperature";
CM_ SG_ 1184 MC_R_Module_A_Temp "IGBT Module A Temperature";

BA_DEF_  "BusType" STRING ;
BA_DEF_ BO_  "GenMsgCycleTime" INT 0 65535;
BA_DEF_ SG_  "GenSigStartValue" FLOAT -3.4E+038 3.4E+038;

BA_DEF_DEF_  "BusType" "CAN";
BA_DEF_DEF_  "GenMsgCycleTime" 0;
BA_DEF_DEF_  "GenSigStartValue" 0;

BA_ "GenMsgCycleTime" BO_ 512 10;
BA_ "GenMsgCycleTime" BO_ 513 10;
BA_ "GenMsgCycleTime" BO_ 514 10;
BA_ "GenMsgCycleTime" BO_ 515 10;
BA_ "GenMsgCycleTime" BO_ 516 10;
BA_ "GenMsgCycleTime" BO_ 517 10;
BA_ "GenMsgCycleTime" BO_ 518 10;
BA_ "GenMsgCycleTime" BO_ 519 10;
BA_ "GenMsgCycleTime" BO_ 528 10;
BA_ "GenMsgCycleTime" BO_ 641 10;
BA_ "GenMsgCycleTime" BO_ 642 10;
BA_ "GenMsgCycleTime" BO_ 643 10;
BA_ "GenMsgCycleTime" BO_ 940 10;
BA_ "GenMsgCycleTime" BO_ 962 10;
BA_ "GenMsgCycleTime" BO_ 961 10;
BA_ "GenMsgCycleTime" BO_ 960 10;
BA_ "GenMsgCycleTime" BO_ 939 100;
BA_ "GenMsgCycleTime" BO_ 938 100;
BA_ "GenMsgCycleTime" BO_ 937 100;
BA_ "GenMsgCycleTime" BO_ 936 10;
BA_ "GenMsgCycleTime" BO_ 935 10;
BA_ "GenMsgCycleTime" BO_ 934 10;
BA_ "GenMsgCycleTime" BO_ 933 10;
BA_ "GenMsgCycleTime" BO_ 932 10;
BA_ "GenMsgCycleTime" BO_ 931 10;
BA_ "GenMsgCycleTime" BO_ 930 100;
BA_ "GenMsgCycleTime" BO_ 929 100;
BA_ "GenMsgCycleTime" BO_ 928 100;
BA_ "GenMsgCycleTime" BO_ 1196 10;
BA_ "GenMsgCycleTime" BO_ 1218 10;
BA_ "GenMsgCycleTime" BO_ 1217 10;
BA_ "GenMsgCycleTime" BO_ 1216 10;
BA_ "GenMsgCycleTime" BO_ 1195 100;
BA_ "GenMsgCycleTime" BO_ 1194 100;
BA_ "GenMsgCycleTime" BO_ 1193 100;
BA_ "GenMsgCycleTime" BO_ 1192 10;
BA_ "GenMsgCycleTime" BO_ 1191 10;
BA_ "GenMsgCycleTime" BO_ 1190 10;
BA_ "GenMsgCycleTime" BO_ 1189 10;
BA_ "GenMsgCycleTime" BO_ 1188 10;
BA_ "GenMsgCycleTime" BO_ 1187 10;
BA_ "GenMsgCycleTime" BO_ 1186 100;
BA_ "GenMsgCycleTime" BO_ 1185 100;
BA_ "GenMsgCycleTime" BO_ 1184 100;

VAL_ 512 SM_State 0 "GLV_ON" 1 "HV_EN" 2 "RTD" 3 "ERROR" 4 "CLEAR_ERROR" 5 "STATE_UNKNOWN" ;
VAL_ 512 Target_State 0 "GLV_ON" 1 "HV_EN" 2 "RTD" 3 "ERROR" 4 "CLEAR_ERROR" 5 "STATE_UNKNOWN" ;
VAL_ 512 Cooling_State 0 "COOLING_OFF" 1 "COOLING_LOW" 2 "COOLING_HIGH" ;
VAL_ 513 CC_State 0 "GLV_ON" 1 "HV_EN" 2 "RTD" 3 "ERROR" 4 "CLEAR_ERROR" 5 "STATE_UNKNOWN" ;
VAL_ 513 CC_Gear 0 "GEAR_SLOW" 1 "GEAR_ENDUR" 2 "GEAR_ACCEL" 3 "GEAR_AUTOX" 4 "GEAR_UNKNOWN" 5 "GEAR_REV" ;
VAL_ 514 FSM_State 0 "GLV_ON" 1 "HV_EN" 2 "RTD" 3 "ERROR" 4 "CLEAR_ERROR" 5 "STATE_UNKNOWN" ;
VAL_ 515 RSM_State 0 "GLV_ON" 1 "HV_EN" 2 "RTD" 3 "ERROR" 4 "CLEAR_ERROR" 5 "STATE_UNKNOWN" ;
VAL_ 515 Radiator_Fan_State 0 "FAN_OFF" 1 "FAN_RAMPING" 2 "FAN_LOW" 3 "FAN_HIGH" 4 "FAN_ERROR" ;
VAL_ 515 Pump_L_Status 1 "PUMP_ON" 0 "PUMP_OFF" ;
VAL_ 515 Pump_R_Status 1 "PUMP_ON" 0 "PUMP_OFF" ;
VAL_ 516 DIM_State 0 "GLV_ON" 1 "HV_EN" 2 "RTD" 3 "ERROR" 4 "CLEAR_ERROR" 5 "STATE_UNKNOWN" ;
VAL_ 516 Requested_State 0 "GLV_ON" 1 "HV_EN" 2 "RTD" 3 "ERROR" 4 "CLEAR_ERROR" 5 "STATE_UNKNOWN" ;
VAL_ 516 Requested_Gear 0 "GEAR_SLOW" 1 "GEAR_ENDUR" 2 "GEAR_ACCEL" 3 "GEAR_AUTOX" 4 "GEAR_UNKNOWN" 5 "GEAR_REV" ;
VAL_ 517 AFC_State 0 "GLV_ON" 1 "HV_EN" 2 "RTD" 3 "ERROR" 4 "CLEAR_ERROR" 5 "STATE_UNKNOWN" ;
VAL_ 517 Fan_3_State 0 "FAN_OFF" 1 "FAN_RAMPING" 2 "FAN_LOW" 3 "FAN_HIGH" 4 "FAN_ERROR" ;
VAL_ 517 Fan_2_State 0 "FAN_OFF" 1 "FAN_RAMPING" 2 "FAN_LOW" 3 "FAN_HIGH" 4 "FAN_ERROR" ;
VAL_ 517 Fan_1_State 0 "FAN_OFF" 1 "FAN_RAMPING" 2 "FAN_LOW" 3 "FAN_HIGH" 4 "FAN_ERROR" ;
VAL_ 518 TM_State 0 "GLV_ON" 1 "HV_EN" 2 "RTD" 3 "ERROR" 4 "CLEAR_ERROR" 5 "STATE_UNKNOWN" ;
VAL_ 519 Comms_State 0 "GLV_ON" 1 "HV_EN" 2 "RTD" 3 "ERROR" 4 "CLEAR_ERROR" 5 "STATE_UNKNOWN" ;
VAL_ 528 Comms_State 0 "GLV_ON" 1 "HV_EN" 2 "RTD" 3 "ERROR" 4 "CLEAR_ERROR" 5 "STATE_UNKNOWN" ;
VAL_ 1527 BMS_Precharge_State 0 "Error" 1 "Idle" 2 "Measure" 3 "Precharge" 4 "Run" 5 "Enable Pack" ;
VAL_ 1541 BMS_Ignition_Switch 0 "BMS_ACCESS" 96 "BMS_START" 32 "BMS_RUN" ;

SIG_VALTYPE_ 1524 BMS_Pack_SOC_Ah : 1;
SIG_VALTYPE_ 1525 BMS_Balance_SOC_Ah : 1;
SIG_VALTYPE_ 1525 BMS_Balance_SOC_Percent : 1;
